VERSION ""

BS_:

BU_:

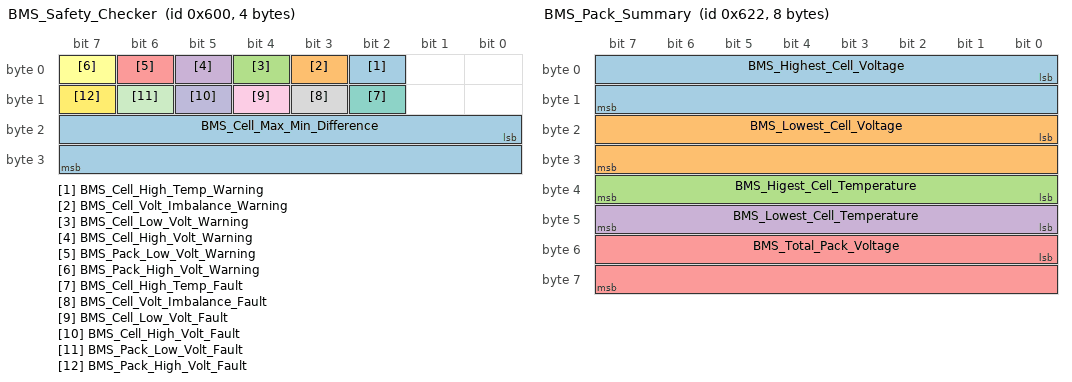
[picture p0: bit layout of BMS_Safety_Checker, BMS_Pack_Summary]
BO_ 1536 BMS_Safety_Checker: 4 Custom_BMS
SG_ BMS_Cell_High_Temp_Warning : 2|1@1- (1,0) [0|1] " " Custom_BMS
SG_ BMS_Cell_Volt_Imbalance_Warning : 3|1@1- (1,0) [0|1] " " Custom_BMS
SG_ BMS_Cell_Low_Volt_Warning : 4|1@1- (1,0) [0|1] " " Custom_BMS
SG_ BMS_Cell_High_Volt_Warning : 5|1@1- (1,0) [0|1] " " Custom_BMS
SG_ BMS_Pack_Low_Volt_Warning : 6|1@1- (1,0) [0|1] " " Custom_BMS
SG_ BMS_Pack_High_Volt_Warning : 7|1@1- (1,0) [0|1] " " Custom_BMS
SG_ BMS_Cell_High_Temp_Fault : 10|1@1- (1,0) [0|1] " " Custom_BMS
SG_ BMS_Cell_Volt_Imbalance_Fault : 11|1@1- (1,0) [0|1] " " Custom_BMS
SG_ BMS_Cell_Low_Volt_Fault : 12|1@1- (1,0) [0|1] " " Custom_BMS
SG_ BMS_Cell_High_Volt_Fault : 13|1@1- (1,0) [0|1] " " Custom_BMS
SG_ BMS_Pack_Low_Volt_Fault : 14|1@1- (1,0) [0|1] " " Custom_BMS
SG_ BMS_Pack_High_Volt_Fault : 15|1@1- (1,0) [0|1] " " Custom_BMS
SG_ BMS_Cell_Max_Min_Difference : 16|16@1+ (0.0001,0) [0|6.5535] "V" Custom_BMS

BO_ 1540 BMS_Balance_Enable: 1 Custom_BMS
SG_ BMS_Balance_Enable : 0|1@1- (1,0) [0|1] " " Custom_BMS

BO_ 1569 BMS_State_of_Charge: 7 Custom_BMS
SG_ BMS_Capacity : 0|16@1+ (1,0) [0|65535] "mAh" Custom_BMS
SG_ BMS_HV_Sense_Pack_Voltage: 16|16@1+ (0.01,0) [0|65535] "V" Custom_BMS
SG_ BMS_Current : 32|32@1+ (1,0) [0|4.29497e+009] "mA" Custom_BMS

BO_ 1571 BMS_Balance_Status_M1_to_M4: 8 Custom_BMS
SG_ BMS_M1_Cell_1 : 0|1@1- (1,0) [0|1] " " Custom_BMS
SG_ BMS_M1_Cell_2 : 1|1@1- (1,0) [0|1] " " Custom_BMS
SG_ BMS_M1_Cell_3 : 2|1@1- (1,0) [0|1] " " Custom_BMS
SG_ BMS_M1_Cell_4 : 3|1@1- (1,0) [0|1] " " Custom_BMS
SG_ BMS_M1_Cell_5 : 4|1@1- (1,0) [0|1] " " Custom_BMS
SG_ BMS_M1_Cell_6 : 5|1@1- (1,0) [0|1] " " Custom_BMS
SG_ BMS_M1_Cell_7 : 6|1@1- (1,0) [0|1] " " Custom_BMS
SG_ BMS_M1_Cell_8 : 7|1@1- (1,0) [0|1] " " Custom_BMS
SG_ BMS_M1_Cell_9 : 8|1@1- (1,0) [0|1] " " Custom_BMS
SG_ BMS_M1_Cell_10 : 9|1@1- (1,0) [0|1] " " Custom_BMS
SG_ BMS_M1_Cell_11 : 10|1@1- (1,0) [0|1] " " Custom_BMS
SG_ BMS_M1_Cell_12 : 11|1@1- (1,0) [0|1] " " Custom_BMS
SG_ BMS_M1_Cell_13 : 12|1@1- (1,0) [0|1] " " Custom_BMS
SG_ BMS_M1_Cell_14 : 13|1@1- (1,0) [0|1] " " Custom_BMS
SG_ BMS_M2_Cell_1 : 16|1@1- (1,0) [0|1] " " Custom_BMS
SG_ BMS_M2_Cell_2 : 17|1@1- (1,0) [0|1] " " Custom_BMS
SG_ BMS_M2_Cell_3 : 18|1@1- (1,0) [0|1] " " Custom_BMS
SG_ BMS_M2_Cell_4 : 19|1@1- (1,0) [0|1] " " Custom_BMS
SG_ BMS_M2_Cell_5 : 20|1@1- (1,0) [0|1] " " Custom_BMS
SG_ BMS_M2_Cell_6 : 21|1@1- (1,0) [0|1] " " Custom_BMS
SG_ BMS_M2_Cell_7 : 22|1@1- (1,0) [0|1] " " Custom_BMS
SG_ BMS_M2_Cell_8 : 23|1@1- (1,0) [0|1] " " Custom_BMS
SG_ BMS_M2_Cell_9 : 24|1@1- (1,0) [0|1] " " Custom_BMS
SG_ BMS_M2_Cell_10 : 25|1@1- (1,0) [0|1] " " Custom_BMS
SG_ BMS_M2_Cell_11 : 26|1@1- (1,0) [0|1] " " Custom_BMS
SG_ BMS_M2_Cell_12 : 27|1@1- (1,0) [0|1] " " Custom_BMS
SG_ BMS_M2_Cell_13 : 28|1@1- (1,0) [0|1] " " Custom_BMS
SG_ BMS_M2_Cell_14 : 29|1@1- (1,0) [0|1] " " Custom_BMS
SG_ BMS_M3_Cell_1 : 32|1@1- (1,0) [0|1] " " Custom_BMS
SG_ BMS_M3_Cell_2 : 33|1@1- (1,0) [0|1] " " Custom_BMS
SG_ BMS_M3_Cell_3 : 34|1@1- (1,0) [0|1] " " Custom_BMS
SG_ BMS_M3_Cell_4 : 35|1@1- (1,0) [0|1] " " Custom_BMS
SG_ BMS_M3_Cell_5 : 36|1@1- (1,0) [0|1] " " Custom_BMS
SG_ BMS_M3_Cell_6 : 37|1@1- (1,0) [0|1] " " Custom_BMS
SG_ BMS_M3_Cell_7 : 38|1@1- (1,0) [0|1] " " Custom_BMS
SG_ BMS_M3_Cell_8 : 39|1@1- (1,0) [0|1] " " Custom_BMS
SG_ BMS_M3_Cell_9 : 40|1@1- (1,0) [0|1] " " Custom_BMS
SG_ BMS_M3_Cell_10 : 41|1@1- (1,0) [0|1] " " Custom_BMS
SG_ BMS_M3_Cell_11 : 42|1@1- (1,0) [0|1] " " Custom_BMS
SG_ BMS_M3_Cell_12 : 43|1@1- (1,0) [0|1] " " Custom_BMS
SG_ BMS_M3_Cell_13 : 44|1@1- (1,0) [0|1] " " Custom_BMS
SG_ BMS_M3_Cell_14 : 45|1@1- (1,0) [0|1] " " Custom_BMS
SG_ BMS_M4_Cell_1 : 48|1@1- (1,0) [0|1] " " Custom_BMS
SG_ BMS_M4_Cell_2 : 49|1@1- (1,0) [0|1] " " Custom_BMS
SG_ BMS_M4_Cell_3 : 50|1@1- (1,0) [0|1] " " Custom_BMS
SG_ BMS_M4_Cell_4 : 51|1@1- (1,0) [0|1] " " Custom_BMS
SG_ BMS_M4_Cell_5 : 52|1@1- (1,0) [0|1] " " Custom_BMS
SG_ BMS_M4_Cell_6 : 53|1@1- (1,0) [0|1] " " Custom_BMS
SG_ BMS_M4_Cell_7 : 54|1@1- (1,0) [0|1] " " Custom_BMS
SG_ BMS_M4_Cell_8 : 55|1@1- (1,0) [0|1] " " Custom_BMS
SG_ BMS_M4_Cell_9 : 56|1@1- (1,0) [0|1] " " Custom_BMS
SG_ BMS_M4_Cell_10 : 57|1@1- (1,0) [0|1] " " Custom_BMS
SG_ BMS_M4_Cell_11 : 58|1@1- (1,0) [0|1] " " Custom_BMS
SG_ BMS_M4_Cell_12 : 59|1@1- (1,0) [0|1] " " Custom_BMS
SG_ BMS_M4_Cell_13 : 60|1@1- (1,0) [0|1] " " Custom_BMS
SG_ BMS_M4_Cell_14 : 61|1@1- (1,0) [0|1] " " Custom_BMS

BO_ 1572 BMS_Balance_Status_M5_to_M8: 8 Custom_BMS
SG_ BMS_M5_Cell_1 : 0|1@1- (1,0) [0|1] " " Custom_BMS
SG_ BMS_M5_Cell_2 : 1|1@1- (1,0) [0|1] " " Custom_BMS
SG_ BMS_M5_Cell_3 : 2|1@1- (1,0) [0|1] " " Custom_BMS
SG_ BMS_M5_Cell_4 : 3|1@1- (1,0) [0|1] " " Custom_BMS
SG_ BMS_M5_Cell_5 : 4|1@1- (1,0) [0|1] " " Custom_BMS
SG_ BMS_M5_Cell_6 : 5|1@1- (1,0) [0|1] " " Custom_BMS
SG_ BMS_M5_Cell_7 : 6|1@1- (1,0) [0|1] " " Custom_BMS
SG_ BMS_M5_Cell_8 : 7|1@1- (1,0) [0|1] " " Custom_BMS
SG_ BMS_M5_Cell_9 : 8|1@1- (1,0) [0|1] " " Custom_BMS
SG_ BMS_M5_Cell_10 : 9|1@1- (1,0) [0|1] " " Custom_BMS
SG_ BMS_M5_Cell_11 : 10|1@1- (1,0) [0|1] " " Custom_BMS
SG_ BMS_M5_Cell_12 : 11|1@1- (1,0) [0|1] " " Custom_BMS
SG_ BMS_M5_Cell_13 : 12|1@1- (1,0) [0|1] " " Custom_BMS
SG_ BMS_M5_Cell_14 : 13|1@1- (1,0) [0|1] " " Custom_BMS
SG_ BMS_M6_Cell_1 : 16|1@1- (1,0) [0|1] " " Custom_BMS
SG_ BMS_M6_Cell_2 : 17|1@1- (1,0) [0|1] " " Custom_BMS
SG_ BMS_M6_Cell_3 : 18|1@1- (1,0) [0|1] " " Custom_BMS
SG_ BMS_M6_Cell_4 : 19|1@1- (1,0) [0|1] " " Custom_BMS
SG_ BMS_M6_Cell_5 : 20|1@1- (1,0) [0|1] " " Custom_BMS
SG_ BMS_M6_Cell_6 : 21|1@1- (1,0) [0|1] " " Custom_BMS
SG_ BMS_M6_Cell_7 : 22|1@1- (1,0) [0|1] " " Custom_BMS
SG_ BMS_M6_Cell_8 : 23|1@1- (1,0) [0|1] " " Custom_BMS
SG_ BMS_M6_Cell_9 : 24|1@1- (1,0) [0|1] " " Custom_BMS
SG_ BMS_M6_Cell_10 : 25|1@1- (1,0) [0|1] " " Custom_BMS
SG_ BMS_M6_Cell_11 : 26|1@1- (1,0) [0|1] " " Custom_BMS
SG_ BMS_M6_Cell_12 : 27|1@1- (1,0) [0|1] " " Custom_BMS
SG_ BMS_M6_Cell_13 : 28|1@1- (1,0) [0|1] " " Custom_BMS
SG_ BMS_M6_Cell_14 : 29|1@1- (1,0) [0|1] " " Custom_BMS
SG_ BMS_M7_Cell_1 : 32|1@1- (1,0) [0|1] " " Custom_BMS
SG_ BMS_M7_Cell_2 : 33|1@1- (1,0) [0|1] " " Custom_BMS
SG_ BMS_M7_Cell_3 : 34|1@1- (1,0) [0|1] " " Custom_BMS
SG_ BMS_M7_Cell_4 : 35|1@1- (1,0) [0|1] " " Custom_BMS
SG_ BMS_M7_Cell_5 : 36|1@1- (1,0) [0|1] " " Custom_BMS
SG_ BMS_M7_Cell_6 : 37|1@1- (1,0) [0|1] " " Custom_BMS
SG_ BMS_M7_Cell_7 : 38|1@1- (1,0) [0|1] " " Custom_BMS
SG_ BMS_M7_Cell_8 : 39|1@1- (1,0) [0|1] " " Custom_BMS
SG_ BMS_M7_Cell_9 : 40|1@1- (1,0) [0|1] " " Custom_BMS
SG_ BMS_M7_Cell_10 : 41|1@1- (1,0) [0|1] " " Custom_BMS
SG_ BMS_M7_Cell_11 : 42|1@1- (1,0) [0|1] " " Custom_BMS
SG_ BMS_M7_Cell_12 : 43|1@1- (1,0) [0|1] " " Custom_BMS
SG_ BMS_M7_Cell_13 : 44|1@1- (1,0) [0|1] " " Custom_BMS
SG_ BMS_M7_Cell_14 : 45|1@1- (1,0) [0|1] " " Custom_BMS
SG_ BMS_M8_Cell_1 : 48|1@1- (1,0) [0|1] " " Custom_BMS
SG_ BMS_M8_Cell_2 : 49|1@1- (1,0) [0|1] " " Custom_BMS
SG_ BMS_M8_Cell_3 : 50|1@1- (1,0) [0|1] " " Custom_BMS
SG_ BMS_M8_Cell_4 : 51|1@1- (1,0) [0|1] " " Custom_BMS
SG_ BMS_M8_Cell_5 : 52|1@1- (1,0) [0|1] " " Custom_BMS
SG_ BMS_M8_Cell_6 : 53|1@1- (1,0) [0|1] " " Custom_BMS
SG_ BMS_M8_Cell_7 : 54|1@1- (1,0) [0|1] " " Custom_BMS
SG_ BMS_M8_Cell_8 : 55|1@1- (1,0) [0|1] " " Custom_BMS
SG_ BMS_M8_Cell_9 : 56|1@1- (1,0) [0|1] " " Custom_BMS
SG_ BMS_M8_Cell_10 : 57|1@1- (1,0) [0|1] " " Custom_BMS
SG_ BMS_M8_Cell_11 : 58|1@1- (1,0) [0|1] " " Custom_BMS
SG_ BMS_M8_Cell_12 : 59|1@1- (1,0) [0|1] " " Custom_BMS
SG_ BMS_M8_Cell_13 : 60|1@1- (1,0) [0|1] " " Custom_BMS
SG_ BMS_M8_Cell_14 : 61|1@1- (1,0) [0|1] " " Custom_BMS

BO_ 1573 BMS_Balance_Status_M9_to_M10: 8 Custom_BMS
SG_ BMS_M9_Cell_1 : 0|1@1- (1,0) [0|1] " " Custom_BMS
SG_ BMS_M9_Cell_2 : 1|1@1- (1,0) [0|1] " " Custom_BMS
SG_ BMS_M9_Cell_3 : 2|1@1- (1,0) [0|1] " " Custom_BMS
SG_ BMS_M9_Cell_4 : 3|1@1- (1,0) [0|1] " " Custom_BMS
SG_ BMS_M9_Cell_5 : 4|1@1- (1,0) [0|1] " " Custom_BMS
SG_ BMS_M9_Cell_6 : 5|1@1- (1,0) [0|1] " " Custom_BMS
SG_ BMS_M9_Cell_7 : 6|1@1- (1,0) [0|1] " " Custom_BMS
SG_ BMS_M9_Cell_8 : 7|1@1- (1,0) [0|1] " " Custom_BMS
SG_ BMS_M9_Cell_9 : 8|1@1- (1,0) [0|1] " " Custom_BMS
SG_ BMS_M9_Cell_10 : 9|1@1- (1,0) [0|1] " " Custom_BMS
SG_ BMS_M9_Cell_11 : 10|1@1- (1,0) [0|1] " " Custom_BMS
SG_ BMS_M9_Cell_12 : 11|1@1- (1,0) [0|1] " " Custom_BMS
SG_ BMS_M9_Cell_13 : 12|1@1- (1,0) [0|1] " " Custom_BMS
SG_ BMS_M9_Cell_14 : 13|1@1- (1,0) [0|1] " " Custom_BMS
SG_ BMS_M10_Cell_1 : 16|1@1- (1,0) [0|1] " " Custom_BMS
SG_ BMS_M10_Cell_2 : 17|1@1- (1,0) [0|1] " " Custom_BMS
SG_ BMS_M10_Cell_3 : 18|1@1- (1,0) [0|1] " " Custom_BMS
SG_ BMS_M10_Cell_4 : 19|1@1- (1,0) [0|1] " " Custom_BMS
SG_ BMS_M10_Cell_5 : 20|1@1- (1,0) [0|1] " " Custom_BMS
SG_ BMS_M10_Cell_6 : 21|1@1- (1,0) [0|1] " " Custom_BMS
SG_ BMS_M10_Cell_7 : 22|1@1- (1,0) [0|1] " " Custom_BMS
SG_ BMS_M10_Cell_8 : 23|1@1- (1,0) [0|1] " " Custom_BMS
SG_ BMS_M10_Cell_9 : 24|1@1- (1,0) [0|1] " " Custom_BMS
SG_ BMS_M10_Cell_10 : 25|1@1- (1,0) [0|1] " " Custom_BMS
SG_ BMS_M10_Cell_11 : 26|1@1- (1,0) [0|1] " " Custom_BMS
SG_ BMS_M10_Cell_12 : 27|1@1- (1,0) [0|1] " " Custom_BMS
SG_ BMS_M10_Cell_13 : 28|1@1- (1,0) [0|1] " " Custom_BMS
SG_ BMS_M10_Cell_14 : 29|1@1- (1,0) [0|1] " " Custom_BMS

BO_ 1570 BMS_Pack_Summary: 8 Custom_BMS
SG_ BMS_Highest_Cell_Voltage : 0|16@1- (0.001,0) [-32.768|32.767] "V" Custom_BMS
SG_ BMS_Lowest_Cell_Voltage : 16|16@1- (0.001,0) [-32.768|32.767] "V" Custom_BMS
SG_ BMS_Higest_Cell_Temperature : 32|8@1+ (1,0) [0|255] "C" Custom_BMS
SG_ BMS_Lowest_Cell_Temperature : 40|8@1+ (1,0) [0|255] "C" Custom_BMS
SG_ BMS_Total_Pack_Voltage   : 48|16@1- (0.001,0) [-32.768|32.767] "V" Custom_BMS

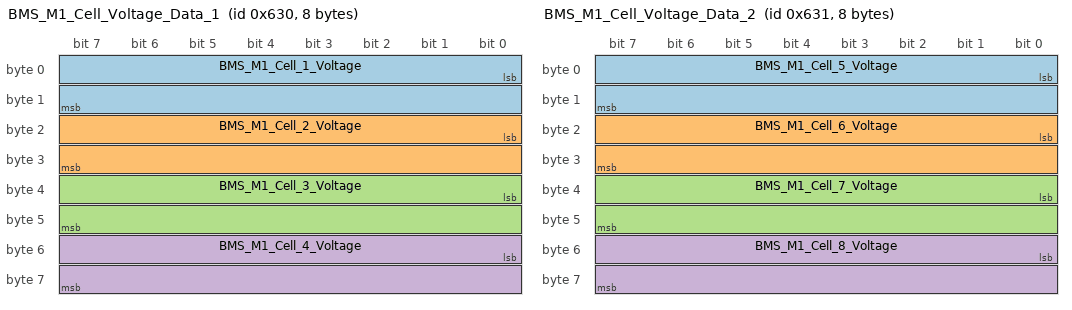
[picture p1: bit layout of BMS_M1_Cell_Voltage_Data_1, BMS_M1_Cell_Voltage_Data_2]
BO_ 1584 BMS_M1_Cell_Voltage_Data_1: 8 Custom_BMS
SG_ BMS_M1_Cell_1_Voltage : 0|16@1- (0.001,0) [-32.768|32.767] "V" Custom_BMS
SG_ BMS_M1_Cell_2_Voltage : 16|16@1- (0.001,0) [-32.768|32.767] "V" Custom_BMS
SG_ BMS_M1_Cell_3_Voltage : 32|16@1- (0.001,0) [-32.768|32.767] "V" Custom_BMS
SG_ BMS_M1_Cell_4_Voltage : 48|16@1- (0.001,0) [-32.768|32.767] "V" Custom_BMS

BO_ 1585 BMS_M1_Cell_Voltage_Data_2: 8 Custom_BMS
SG_ BMS_M1_Cell_5_Voltage : 0|16@1- (0.001,0) [-32.768|32.767] "V" Custom_BMS
SG_ BMS_M1_Cell_6_Voltage : 16|16@1- (0.001,0) [-32.768|32.767] "V" Custom_BMS
SG_ BMS_M1_Cell_7_Voltage : 32|16@1- (0.001,0) [-32.768|32.767] "V" Custom_BMS
SG_ BMS_M1_Cell_8_Voltage : 48|16@1- (0.001,0) [-32.768|32.767] "V" Custom_BMS

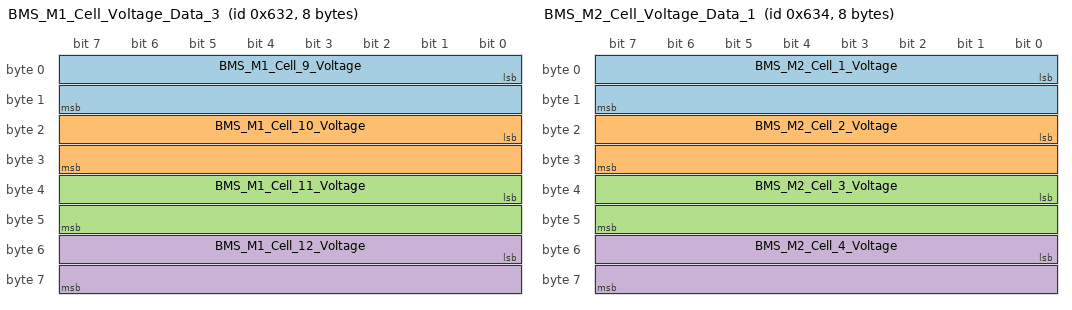
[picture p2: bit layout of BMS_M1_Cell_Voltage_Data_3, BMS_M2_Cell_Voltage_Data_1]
BO_ 1586 BMS_M1_Cell_Voltage_Data_3: 8 Custom_BMS
SG_ BMS_M1_Cell_9_Voltage  : 0|16@1- (0.001,0) [-32.768|32.767] "V" Custom_BMS
SG_ BMS_M1_Cell_10_Voltage : 16|16@1- (0.001,0) [-32.768|32.767] "V" Custom_BMS
SG_ BMS_M1_Cell_11_Voltage : 32|16@1- (0.001,0) [-32.768|32.767] "V" Custom_BMS
SG_ BMS_M1_Cell_12_Voltage : 48|16@1- (0.001,0) [-32.768|32.767] "V" Custom_BMS

BO_ 1587 BMS_M1_Cell_Voltage_Data_4: 4 Custom_BMS
SG_ BMS_M1_Cell_13_Voltage : 0|16@1- (0.001,0) [-32.768|32.767] "V" Custom_BMS
SG_ BMS_M1_Cell_14_Voltage : 16|16@1- (0.001,0) [-32.768|32.767] "V" Custom_BMS	CM_ check

BO_ 1588 BMS_M2_Cell_Voltage_Data_1: 8 Custom_BMS
SG_ BMS_M2_Cell_1_Voltage : 0|16@1- (0.001,0) [-32.768|32.767] "V" Custom_BMS
SG_ BMS_M2_Cell_2_Voltage : 16|16@1- (0.001,0) [-32.768|32.767] "V" Custom_BMS
SG_ BMS_M2_Cell_3_Voltage : 32|16@1- (0.001,0) [-32.768|32.767] "V" Custom_BMS
SG_ BMS_M2_Cell_4_Voltage : 48|16@1- (0.001,0) [-32.768|32.767] "V" Custom_BMS

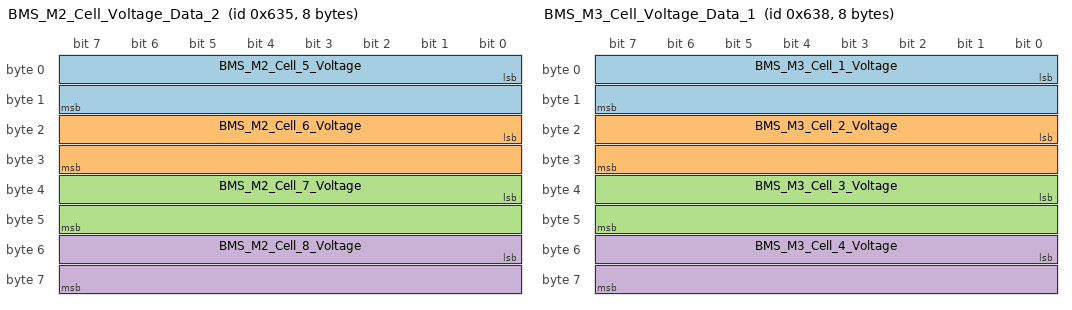
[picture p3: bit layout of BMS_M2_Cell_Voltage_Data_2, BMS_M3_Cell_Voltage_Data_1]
BO_ 1589 BMS_M2_Cell_Voltage_Data_2: 8 Custom_BMS
SG_ BMS_M2_Cell_5_Voltage : 0|16@1- (0.001,0) [-32.768|32.767] "V" Custom_BMS
SG_ BMS_M2_Cell_6_Voltage : 16|16@1- (0.001,0) [-32.768|32.767] "V" Custom_BMS
SG_ BMS_M2_Cell_7_Voltage : 32|16@1- (0.001,0) [-32.768|32.767] "V" Custom_BMS
SG_ BMS_M2_Cell_8_Voltage : 48|16@1- (0.001,0) [-32.768|32.767] "V" Custom_BMS

BO_ 1590 BMS_M2_Cell_Voltage_Data_3: 8 Custom_BMS
SG_ BMS_M2_Cell_9_Voltage  : 0|16@1- (0.001,0) [-32.768|32.767] "V" Custom_BMS
SG_ BMS_M2_Cell_10_Voltage : 16|16@1- (0.001,0) [-32.768|32.767] "V" Custom_BMS
SG_ BMS_M2_Cell_11_Voltage : 32|16@1- (0.001,0) [-32.768|32.767] "V" Custom_BMS
SG_ BMS_M2_Cell_12_Voltage : 48|16@1- (0.001,0) [-32.768|32.767] "V" Custom_BMS

B0_ 1591 BMS_M2_Cell_Voltage_data_4: 4 Custom_BMS
SG_ BMS_M2_Cell_13_Voltage : 0|16@1- (0.001,0) [-32.768|32.767] "V" Custom_BMS
SG_ BMS_M2_Cell_14_voltage : 16|16@1- (0.001,0) [-32.768|32.767] "V" Custom_BMS	CM_check

BO_ 1592 BMS_M3_Cell_Voltage_Data_1: 8 Custom_BMS
SG_ BMS_M3_Cell_1_Voltage : 0|16@1- (0.001,0) [-32.768|32.767] "V" Custom_BMS
SG_ BMS_M3_Cell_2_Voltage : 16|16@1- (0.001,0) [-32.768|32.767] "V" Custom_BMS
SG_ BMS_M3_Cell_3_Voltage : 32|16@1- (0.001,0) [-32.768|32.767] "V" Custom_BMS
SG_ BMS_M3_Cell_4_Voltage : 48|16@1- (0.001,0) [-32.768|32.767] "V" Custom_BMS

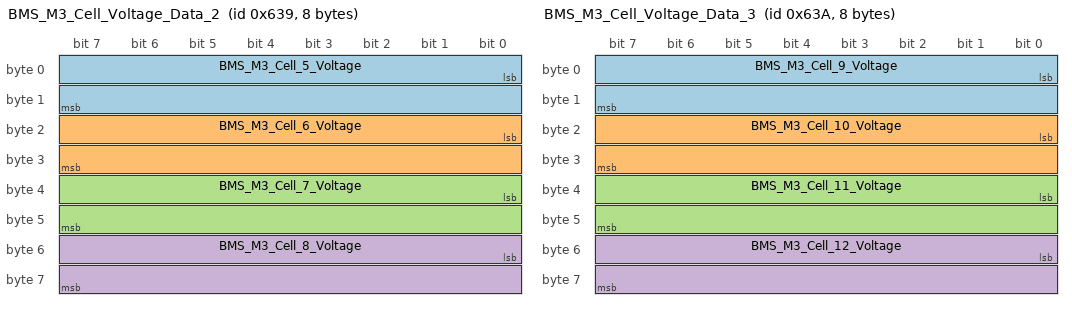
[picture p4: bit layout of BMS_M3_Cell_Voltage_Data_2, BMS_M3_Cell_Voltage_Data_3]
BO_ 1593 BMS_M3_Cell_Voltage_Data_2: 8 Custom_BMS
SG_ BMS_M3_Cell_5_Voltage : 0|16@1- (0.001,0) [-32.768|32.767] "V" Custom_BMS
SG_ BMS_M3_Cell_6_Voltage : 16|16@1- (0.001,0) [-32.768|32.767] "V" Custom_BMS
SG_ BMS_M3_Cell_7_Voltage : 32|16@1- (0.001,0) [-32.768|32.767] "V" Custom_BMS
SG_ BMS_M3_Cell_8_Voltage : 48|16@1- (0.001,0) [-32.768|32.767] "V" Custom_BMS

BO_ 1594 BMS_M3_Cell_Voltage_Data_3: 8 Custom_BMS
SG_ BMS_M3_Cell_9_Voltage  : 0|16@1- (0.001,0) [-32.768|32.767] "V" Custom_BMS
SG_ BMS_M3_Cell_10_Voltage : 16|16@1- (0.001,0) [-32.768|32.767] "V" Custom_BMS
SG_ BMS_M3_Cell_11_Voltage : 32|16@1- (0.001,0) [-32.768|32.767] "V" Custom_BMS
SG_ BMS_M3_Cell_12_Voltage : 48|16@1- (0.001,0) [-32.768|32.767] "V" Custom_BMS

BO_ 1595 BMS_M3_Cell_Voltage_Data_4: 4 Custom_BMS
SG_ BMS_M3_Cell_13_Voltage : 0|16@1- (0.001,0) [-32.768|32.767] "V" Custom_BMS
SG_ BMS_M3_Cell_14_Voltage : 16|16@1- (0.001,0) [-32.768|32.767] "V" Custom_BMS	CM_ check

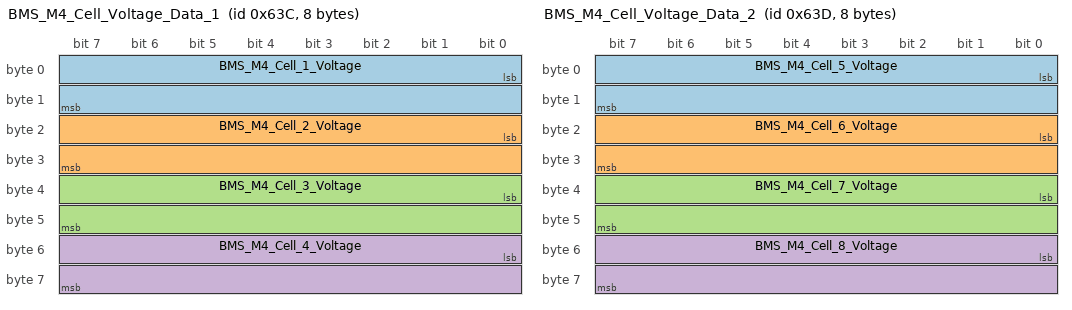
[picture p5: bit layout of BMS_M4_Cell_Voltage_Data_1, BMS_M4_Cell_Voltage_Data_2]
BO_ 1596 BMS_M4_Cell_Voltage_Data_1: 8 Custom_BMS
SG_ BMS_M4_Cell_1_Voltage : 0|16@1- (0.001,0) [-32.768|32.767] "V" Custom_BMS
SG_ BMS_M4_Cell_2_Voltage : 16|16@1- (0.001,0) [-32.768|32.767] "V" Custom_BMS
SG_ BMS_M4_Cell_3_Voltage : 32|16@1- (0.001,0) [-32.768|32.767] "V" Custom_BMS
SG_ BMS_M4_Cell_4_Voltage : 48|16@1- (0.001,0) [-32.768|32.767] "V" Custom_BMS

BO_ 1597 BMS_M4_Cell_Voltage_Data_2: 8 Custom_BMS
SG_ BMS_M4_Cell_5_Voltage : 0|16@1- (0.001,0) [-32.768|32.767] "V" Custom_BMS
SG_ BMS_M4_Cell_6_Voltage : 16|16@1- (0.001,0) [-32.768|32.767] "V" Custom_BMS
SG_ BMS_M4_Cell_7_Voltage : 32|16@1- (0.001,0) [-32.768|32.767] "V" Custom_BMS
SG_ BMS_M4_Cell_8_Voltage : 48|16@1- (0.001,0) [-32.768|32.767] "V" Custom_BMS

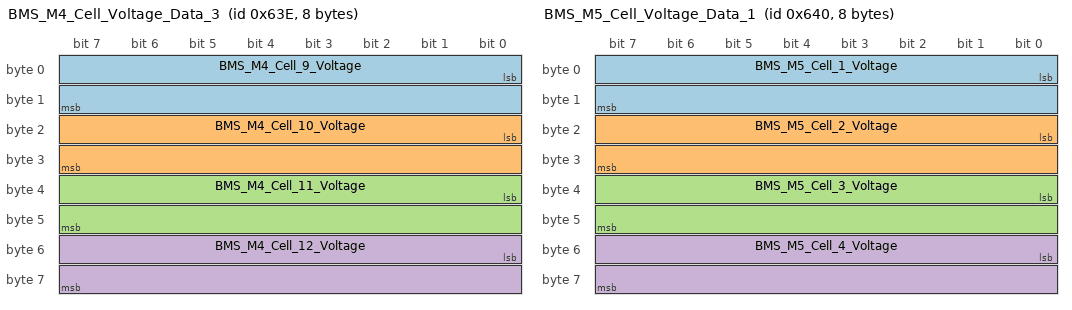
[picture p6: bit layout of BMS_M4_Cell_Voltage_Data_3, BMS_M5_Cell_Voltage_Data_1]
BO_ 1598 BMS_M4_Cell_Voltage_Data_3: 8 Custom_BMS
SG_ BMS_M4_Cell_9_Voltage  : 0|16@1- (0.001,0) [-32.768|32.767] "V" Custom_BMS
SG_ BMS_M4_Cell_10_Voltage : 16|16@1- (0.001,0) [-32.768|32.767] "V" Custom_BMS
SG_ BMS_M4_Cell_11_Voltage : 32|16@1- (0.001,0) [-32.768|32.767] "V" Custom_BMS
SG_ BMS_M4_Cell_12_Voltage : 48|16@1- (0.001,0) [-32.768|32.767] "V" Custom_BMS

BO_ 1599 BMS_M4_Cell_Voltage_Data_4: 4 Custom_BMS
SG_ BMS_M4_Cell_13_Voltage : 0|16@1- (0.001,0) [-32.768|32.767] "V" Custom_BMS
SG_ BMS_M4_Cell_14_Voltage : 16|16@1- (0.001,0) [-32.768|32.767] "V" Custom_BMS	CM_ check 32 bits

BO_ 1600 BMS_M5_Cell_Voltage_Data_1: 8 Custom_BMS
SG_ BMS_M5_Cell_1_Voltage : 0|16@1- (0.001,0) [-32.768|32.767] "V" Custom_BMS
SG_ BMS_M5_Cell_2_Voltage : 16|16@1- (0.001,0) [-32.768|32.767] "V" Custom_BMS
SG_ BMS_M5_Cell_3_Voltage : 32|16@1- (0.001,0) [-32.768|32.767] "V" Custom_BMS
SG_ BMS_M5_Cell_4_Voltage : 48|16@1- (0.001,0) [-32.768|32.767] "V" Custom_BMS

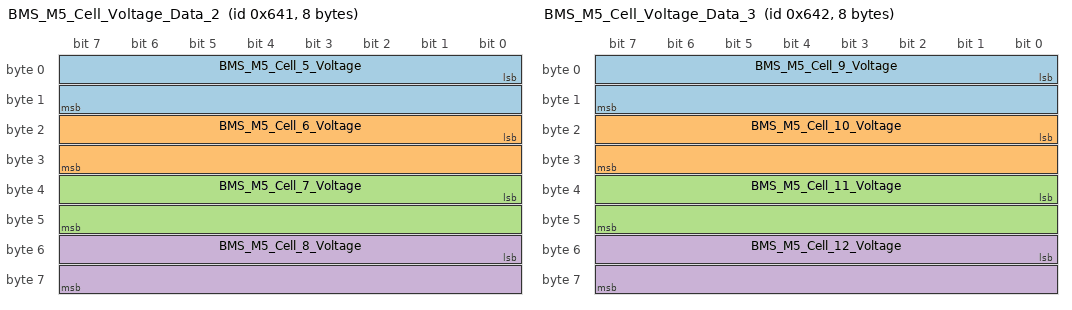
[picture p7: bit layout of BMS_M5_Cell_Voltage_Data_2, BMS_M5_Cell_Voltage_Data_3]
BO_ 1601 BMS_M5_Cell_Voltage_Data_2: 8 Custom_BMS
SG_ BMS_M5_Cell_5_Voltage : 0|16@1- (0.001,0) [-32.768|32.767] "V" Custom_BMS
SG_ BMS_M5_Cell_6_Voltage : 16|16@1- (0.001,0) [-32.768|32.767] "V" Custom_BMS
SG_ BMS_M5_Cell_7_Voltage : 32|16@1- (0.001,0) [-32.768|32.767] "V" Custom_BMS
SG_ BMS_M5_Cell_8_Voltage : 48|16@1- (0.001,0) [-32.768|32.767] "V" Custom_BMS

BO_ 1602 BMS_M5_Cell_Voltage_Data_3: 8 Custom_BMS
SG_ BMS_M5_Cell_9_Voltage  : 0|16@1- (0.001,0) [-32.768|32.767] "V" Custom_BMS
SG_ BMS_M5_Cell_10_Voltage : 16|16@1- (0.001,0) [-32.768|32.767] "V" Custom_BMS
SG_ BMS_M5_Cell_11_Voltage : 32|16@1- (0.001,0) [-32.768|32.767] "V" Custom_BMS
SG_ BMS_M5_Cell_12_Voltage : 48|16@1- (0.001,0) [-32.768|32.767] "V" Custom_BMS

BO_ 1603 BMS_M5_Cell_Voltage_Data_4: 4 Custom_BMS
SG_ BMS_M5_Cell_13_Voltage : 0|16@1- (0.001,0) [-32.768|32.767] "V" Custom_BMS
SG_ BMS_M5_Cell_14_Voltage : 16|16@1- (0.001,0) [-32.768|32.767] "V" Custom_BMS CM_check

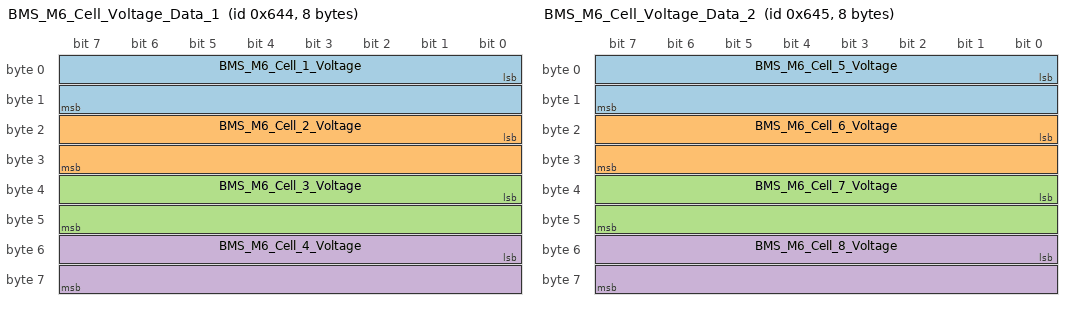
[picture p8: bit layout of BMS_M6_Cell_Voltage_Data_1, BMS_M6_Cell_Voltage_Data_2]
BO_ 1604 BMS_M6_Cell_Voltage_Data_1: 8 Custom_BMS
SG_ BMS_M6_Cell_1_Voltage : 0|16@1- (0.001,0) [-32.768|32.767] "V" Custom_BMS
SG_ BMS_M6_Cell_2_Voltage : 16|16@1- (0.001,0) [-32.768|32.767] "V" Custom_BMS
SG_ BMS_M6_Cell_3_Voltage : 32|16@1- (0.001,0) [-32.768|32.767] "V" Custom_BMS
SG_ BMS_M6_Cell_4_Voltage : 48|16@1- (0.001,0) [-32.768|32.767] "V" Custom_BMS

BO_ 1605 BMS_M6_Cell_Voltage_Data_2: 8 Custom_BMS
SG_ BMS_M6_Cell_5_Voltage : 0|16@1- (0.001,0) [-32.768|32.767] "V" Custom_BMS
SG_ BMS_M6_Cell_6_Voltage : 16|16@1- (0.001,0) [-32.768|32.767] "V" Custom_BMS
SG_ BMS_M6_Cell_7_Voltage : 32|16@1- (0.001,0) [-32.768|32.767] "V" Custom_BMS
SG_ BMS_M6_Cell_8_Voltage : 48|16@1- (0.001,0) [-32.768|32.767] "V" Custom_BMS

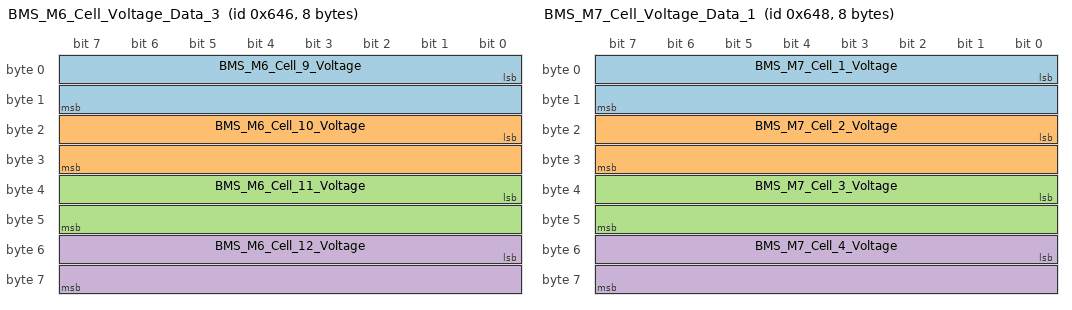
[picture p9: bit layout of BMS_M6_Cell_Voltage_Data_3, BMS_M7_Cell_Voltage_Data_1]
BO_ 1606 BMS_M6_Cell_Voltage_Data_3: 8 Custom_BMS
SG_ BMS_M6_Cell_9_Voltage  : 0|16@1- (0.001,0) [-32.768|32.767] "V" Custom_BMS
SG_ BMS_M6_Cell_10_Voltage : 16|16@1- (0.001,0) [-32.768|32.767] "V" Custom_BMS
SG_ BMS_M6_Cell_11_Voltage : 32|16@1- (0.001,0) [-32.768|32.767] "V" Custom_BMS
SG_ BMS_M6_Cell_12_Voltage : 48|16@1- (0.001,0) [-32.768|32.767] "V" Custom_BMS

BO_ 1607 BMS_M6_Cell_Voltage_Data_4: 4 Custom_BMS
SG_ BMS_M6_Cell_13_Voltage : 0|16@1- (0.001,0) [-32.768|32.767] "V" Custom_BMS
SG_ BMS_M6_Cell_14_Voltage : 16|16@1- (0.001,0) [-32.768|32.767] "V" Custom_BMS		CM_ check

BO_ 1608 BMS_M7_Cell_Voltage_Data_1: 8 Custom_BMS
SG_ BMS_M7_Cell_1_Voltage : 0|16@1- (0.001,0) [-32.768|32.767] "V" Custom_BMS
SG_ BMS_M7_Cell_2_Voltage : 16|16@1- (0.001,0) [-32.768|32.767] "V" Custom_BMS
SG_ BMS_M7_Cell_3_Voltage : 32|16@1- (0.001,0) [-32.768|32.767] "V" Custom_BMS
SG_ BMS_M7_Cell_4_Voltage : 48|16@1- (0.001,0) [-32.768|32.767] "V" Custom_BMS

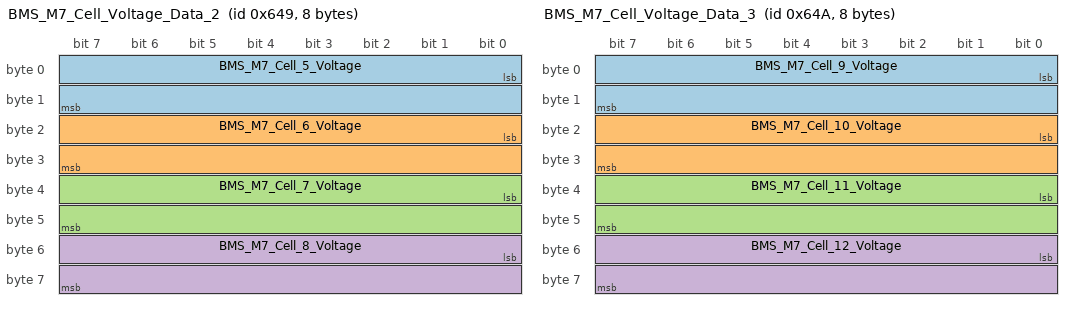
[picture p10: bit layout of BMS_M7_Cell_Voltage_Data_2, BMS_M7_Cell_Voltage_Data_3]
BO_ 1609 BMS_M7_Cell_Voltage_Data_2: 8 Custom_BMS
SG_ BMS_M7_Cell_5_Voltage : 0|16@1- (0.001,0) [-32.768|32.767] "V" Custom_BMS
SG_ BMS_M7_Cell_6_Voltage : 16|16@1- (0.001,0) [-32.768|32.767] "V" Custom_BMS
SG_ BMS_M7_Cell_7_Voltage : 32|16@1- (0.001,0) [-32.768|32.767] "V" Custom_BMS
SG_ BMS_M7_Cell_8_Voltage : 48|16@1- (0.001,0) [-32.768|32.767] "V" Custom_BMS

BO_ 1610 BMS_M7_Cell_Voltage_Data_3: 8 Custom_BMS
SG_ BMS_M7_Cell_9_Voltage  : 0|16@1- (0.001,0) [-32.768|32.767] "V" Custom_BMS
SG_ BMS_M7_Cell_10_Voltage : 16|16@1- (0.001,0) [-32.768|32.767] "V" Custom_BMS
SG_ BMS_M7_Cell_11_Voltage : 32|16@1- (0.001,0) [-32.768|32.767] "V" Custom_BMS
SG_ BMS_M7_Cell_12_Voltage : 48|16@1- (0.001,0) [-32.768|32.767] "V" Custom_BMS

BO_ 1611 BMS_M7_Cell_Voltage_Data_4: 4 Custom_BMS
SG_ BMS_M7_Cell_13_Voltage : 0|16@1- (0.001,0) [-32.768|32.767] "V" Custom_BMS
SG_ BMS_M7_Cell_14_Voltage : 16|16@1- (0.001,0) [-32.768|32.767] "V" Custom_BMS	CM_ check

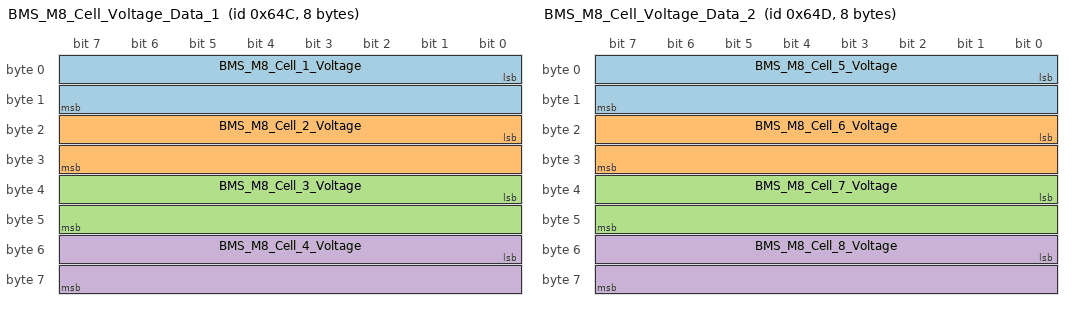
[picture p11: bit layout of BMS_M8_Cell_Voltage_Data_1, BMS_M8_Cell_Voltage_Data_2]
BO_ 1612 BMS_M8_Cell_Voltage_Data_1: 8 Custom_BMS
SG_ BMS_M8_Cell_1_Voltage : 0|16@1- (0.001,0) [-32.768|32.767] "V" Custom_BMS
SG_ BMS_M8_Cell_2_Voltage : 16|16@1- (0.001,0) [-32.768|32.767] "V" Custom_BMS
SG_ BMS_M8_Cell_3_Voltage : 32|16@1- (0.001,0) [-32.768|32.767] "V" Custom_BMS
SG_ BMS_M8_Cell_4_Voltage : 48|16@1- (0.001,0) [-32.768|32.767] "V" Custom_BMS

BO_ 1613 BMS_M8_Cell_Voltage_Data_2: 8 Custom_BMS
SG_ BMS_M8_Cell_5_Voltage : 0|16@1- (0.001,0) [-32.768|32.767] "V" Custom_BMS
SG_ BMS_M8_Cell_6_Voltage : 16|16@1- (0.001,0) [-32.768|32.767] "V" Custom_BMS
SG_ BMS_M8_Cell_7_Voltage : 32|16@1- (0.001,0) [-32.768|32.767] "V" Custom_BMS
SG_ BMS_M8_Cell_8_Voltage : 48|16@1- (0.001,0) [-32.768|32.767] "V" Custom_BMS

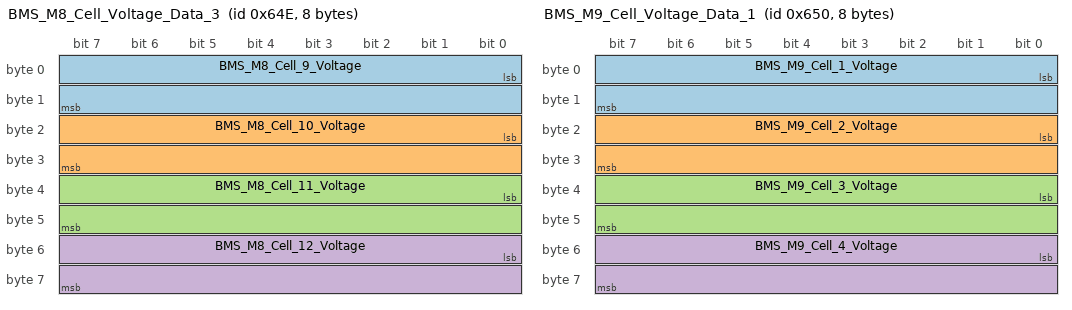
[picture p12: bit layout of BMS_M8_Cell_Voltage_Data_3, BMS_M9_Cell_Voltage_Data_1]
BO_ 1614 BMS_M8_Cell_Voltage_Data_3: 8 Custom_BMS
SG_ BMS_M8_Cell_9_Voltage  : 0|16@1- (0.001,0) [-32.768|32.767] "V" Custom_BMS
SG_ BMS_M8_Cell_10_Voltage : 16|16@1- (0.001,0) [-32.768|32.767] "V" Custom_BMS
SG_ BMS_M8_Cell_11_Voltage : 32|16@1- (0.001,0) [-32.768|32.767] "V" Custom_BMS
SG_ BMS_M8_Cell_12_Voltage : 48|16@1- (0.001,0) [-32.768|32.767] "V" Custom_BMS

BO_ 1615 BMS_M8_Cell_Voltage_Data_4: 4 Custom_BMS
SG_ BMS_M8_Cell_13_Voltage : 0|16@1- (0.001,0) [-32.768|32.767] "V" Custom_BMS
SG_ BMS_M8_Cell_14_Voltage : 16|16@1- (0.001,0) [-32.768|32.767] "V" Custom_BMS	CM_ check

BO_ 1616 BMS_M9_Cell_Voltage_Data_1: 8 Custom_BMS
SG_ BMS_M9_Cell_1_Voltage : 0|16@1- (0.001,0) [-32.768|32.767] "V" Custom_BMS
SG_ BMS_M9_Cell_2_Voltage : 16|16@1- (0.001,0) [-32.768|32.767] "V" Custom_BMS
SG_ BMS_M9_Cell_3_Voltage : 32|16@1- (0.001,0) [-32.768|32.767] "V" Custom_BMS
SG_ BMS_M9_Cell_4_Voltage : 48|16@1- (0.001,0) [-32.768|32.767] "V" Custom_BMS

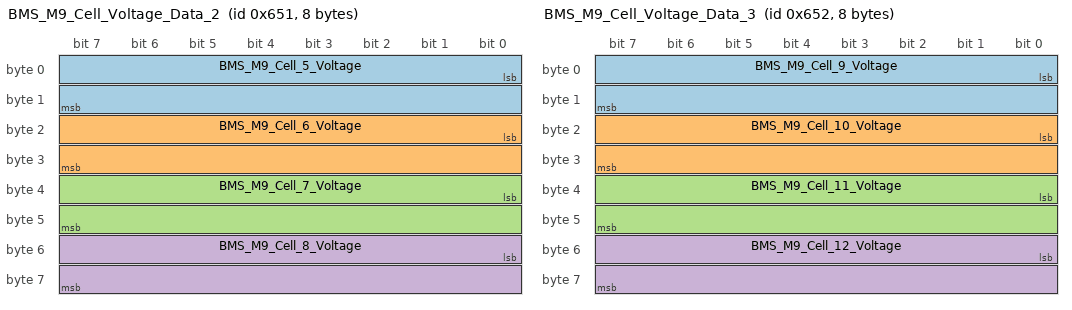
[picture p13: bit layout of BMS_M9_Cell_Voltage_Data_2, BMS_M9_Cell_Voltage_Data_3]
BO_ 1617 BMS_M9_Cell_Voltage_Data_2: 8 Custom_BMS
SG_ BMS_M9_Cell_5_Voltage : 0|16@1- (0.001,0) [-32.768|32.767] "V" Custom_BMS
SG_ BMS_M9_Cell_6_Voltage : 16|16@1- (0.001,0) [-32.768|32.767] "V" Custom_BMS
SG_ BMS_M9_Cell_7_Voltage : 32|16@1- (0.001,0) [-32.768|32.767] "V" Custom_BMS
SG_ BMS_M9_Cell_8_Voltage : 48|16@1- (0.001,0) [-32.768|32.767] "V" Custom_BMS

BO_ 1618 BMS_M9_Cell_Voltage_Data_3: 8 Custom_BMS
SG_ BMS_M9_Cell_9_Voltage  : 0|16@1- (0.001,0) [-32.768|32.767] "V" Custom_BMS
SG_ BMS_M9_Cell_10_Voltage : 16|16@1- (0.001,0) [-32.768|32.767] "V" Custom_BMS
SG_ BMS_M9_Cell_11_Voltage : 32|16@1- (0.001,0) [-32.768|32.767] "V" Custom_BMS
SG_ BMS_M9_Cell_12_Voltage : 48|16@1- (0.001,0) [-32.768|32.767] "V" Custom_BMS

BO_ 1619 BMS_M9_Cell_Voltage_Data_4: 4 Custom_BMS
SG_ BMS_M9_Cell_13_Voltage : 0|16@1- (0.001,0) [-32.768|32.767] "V" Custom_BMS
SG_ BMS_M9_Cell_14_Voltage : 16|16@1- (0.001,0) [-32.768|32.767] "V" Custom_BMS	CM_ check

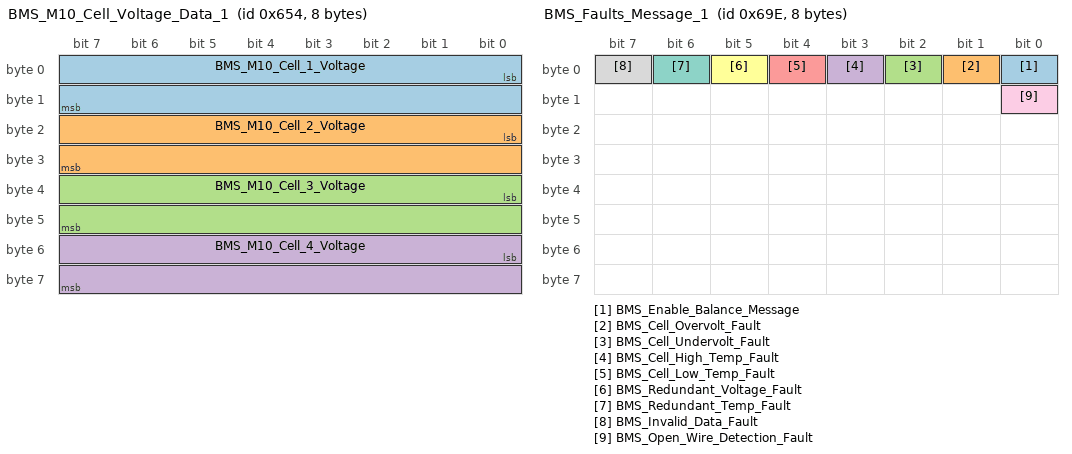
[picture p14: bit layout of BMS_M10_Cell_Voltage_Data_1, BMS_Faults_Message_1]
BO_ 1620 BMS_M10_Cell_Voltage_Data_1: 8 Custom_BMS
SG_ BMS_M10_Cell_1_Voltage : 0|16@1- (0.001,0) [-32.768|32.767] "V" Custom_BMS
SG_ BMS_M10_Cell_2_Voltage : 16|16@1- (0.001,0) [-32.768|32.767] "V" Custom_BMS
SG_ BMS_M10_Cell_3_Voltage : 32|16@1- (0.001,0) [-32.768|32.767] "V" Custom_BMS
SG_ BMS_M10_Cell_4_Voltage : 48|16@1- (0.001,0) [-32.768|32.767] "V" Custom_BMS

BO_ 1621 BMS_M10_Cell_Voltage_Data_2: 8 Custom_BMS
SG_ BMS_M10_Cell_5_Voltage : 0|16@1- (0.001,0) [-32.768|32.767] "V" Custom_BMS
SG_ BMS_M10_Cell_6_Voltage : 16|16@1- (0.001,0) [-32.768|32.767] "V" Custom_BMS
SG_ BMS_M10_Cell_7_Voltage : 32|16@1- (0.001,0) [-32.768|32.767] "V" Custom_BMS
SG_ BMS_M10_Cell_8_Voltage : 48|16@1- (0.001,0) [-32.768|32.767] "V" Custom_BMS

BO_ 1622 BMS_M10_Cell_Voltage_Data_3: 8 Custom_BMS
SG_ BMS_M10_Cell_9_Voltage  : 0|16@1- (0.001,0) [-32.768|32.767] "V" Custom_BMS
SG_ BMS_M10_Cell_10_Voltage : 16|16@1- (0.001,0) [-32.768|32.767] "V" Custom_BMS
SG_ BMS_M10_Cell_11_Voltage : 32|16@1- (0.001,0) [-32.768|32.767] "V" Custom_BMS
SG_ BMS_M10_Cell_12_Voltage : 48|16@1- (0.001,0) [-32.768|32.767] "V" Custom_BMS

BO_ 1623 BMS_M10_Cell_Voltage_Data_4: 4 Custom_BMS
SG_ BMS_M10_Cell_13_Voltage : 0|16@1- (0.001,0) [-32.768|32.767] "V" Custom_BMS
SG_ BMS_M10_Cell_14_Voltage : 16|16@1- (0.001,0) [-32.768|32.767] "V" Custom_BMS	CM_ check

BO_ 1664 BMS_M1_Cell_Thermistor_Data_1: 8 Custom_BMS
SG_ BMS_M1_Cell_position1_Thermistor : 0|16@1+ (1,0) [0|255] "C" Custom_BMS
SG_ BMS_M1_Cell_position2_Thermistor : 16|16@1+ (1,0) [0|255] "C" Custom_BMS CM_check changed to 16 bytes for each thermistor
SG_ BMS_M1_Cell_position3_Thermistor : 32|16@1+ (1,0) [0|255] "C" Custom_BMS
SG_ BMS_M1_Cell_position4_Thermistor : 48|16@1+ (1,0) [0|255] "C" Custom_BMS

BO_ 1665 BMS_M1_Cell_Thermistor_Data_2: 8 Custom_BMS
SG_ BMS_M1_Cell_position5_Thermistor : 0|16@1+ (1,0) [0|255] "C" Custom_BMS
SG_ BMS_M1_Cell_position6_Thermistor : 16|16@1+ (1,0) [0|255] "C" Custom_BMS
SG_ BMS_M1_Cell_position7_Thermistor : 32|16@1+ (1,0) [0|255] "C" Custom_BMS
SG_ BMS_M1_Cell_position8_Thermistor : 48|16@1+ (1,0) [0|255] "C" Custom_BMS CM_check thermistor 10 temp read    deleted pressure,humidity, atmosphere, dewpoint

BO_ 1666 BMS_M1_Cell_Thermistor_Data_3: 4 Custom_BMS
SG_ BMS_M1_Cell_position9_Thermistor  : 0|16@1+ (1,0) [0|255] "C" Custom_BMS CM_check add more stuff into the messages
SG_ BMS_M1_Cell_position10_Thermistor : 16|16@1+ (1,0) [0|255] "C" Custom_BMS

BO_ 1667 BMS_M2_Cell_Thermistor_Data_1: 8 Custom_BMS
SG_ BMS_M2_Cell_position1_Thermistor : 0|16@1+ (1,0) [0|255] "C" Custom_BMS
SG_ BMS_M2_Cell_position2_Thermistor : 16|16@1+ (1,0) [0|255] "C" Custom_BMS
SG_ BMS_M2_Cell_position3_Thermistor : 32|16@1+ (1,0) [0|255] "C" Custom_BMS
SG_ BMS_M2_Cell_position4_Thermistor : 48|16@1+ (1,0) [0|255] "C" Custom_BMS

BO_ 1668 BMS_M2_Cell_Thermistor_Data_2: 8 Custom_BMS
SG_ BMS_M2_Cell_position5_Thermistor : 0|16@1+ (1,0) [0|255] "C" Custom_BMS
SG_ BMS_M2_Cell_position6_Thermistor : 16|16@1+ (1,0) [0|255] "C" Custom_BMS
SG_ BMS_M2_Cell_position7_Thermistor : 32|16@1+ (1,0) [0|255] "C" Custom_BMS
SG_ BMS_M2_Cell_position8_Thermistor : 48|16@1+ (1,0) [0|255] "C" Custom_BMS

BO_ 1669 BMS_M2_Cell_Thermistor_Data_3: 4 Custom_BMS
SG_ BMS_M2_Cell_position9_Thermistor  : 0|16@1+ (1,0) [0|255] "C" Custom_BMS
SG_ BMS_M2_Cell_position10_Thermistor : 16|16@1+ (1,0) [0|255] "C" Custom_BMS CM_check thermistor 10 readings delete dew point, atmosphere temp,pressure, humidity

BO_ 1670 BMS_M3_Cell_Thermistor_Data_1: 8 Custom_BMS
SG_ BMS_M3_Cell_position1_Thermistor : 0|16@1+ (1,0) [0|255] "C" Custom_BMS
SG_ BMS_M3_Cell_position2_Thermistor : 16|16@1+ (1,0) [0|255] "C" Custom_BMS
SG_ BMS_M3_Cell_position3_Thermistor : 32|16@1+ (1,0) [0|255] "C" Custom_BMS
SG_ BMS_M3_Cell_position4_Thermistor : 48|16@1+ (1,0) [0|255] "C" Custom_BMS

BO_ 1671 BMS_M3_Cell_Thermistor_Data_2: 8 Custom_BMS
SG_ BMS_M3_Cell_position5_Thermistor : 0|16@1+ (1,0) [0|255] "C" Custom_BMS
SG_ BMS_M3_Cell_position6_Thermistor : 16|16@1+ (1,0) [0|255] "C" Custom_BMS
SG_ BMS_M3_Cell_position7_Thermistor : 32|16@1+ (1,0) [0|255] "C" Custom_BMS
SG_ BMS_M3_Cell_position8_Thermistor : 48|16@1+ (1,0) [0|255] "C" Custom_BMS

BO_ 1672 BMS_M3_Cell_Thermistor_Data_3: 4 Custom_BMS
SG_ BMS_M3_Cell_position9_Thermistor  : 0|16@1+ (1,0) [0|255] "C" Custom_BMS
SG_ BMS_M3_Cell_position10_Thermistor : 16|16@1+ (1,0) [0|255] "C" Custom_BMS CM_check thermistor 10 readings

BO_ 1673 BMS_M4_Cell_Thermistor_Data_1: 8 Custom_BMS
SG_ BMS_M4_Cell_position1_Thermistor : 0|16@1+ (1,0) [0|255] "C" Custom_BMS
SG_ BMS_M4_Cell_position2_Thermistor : 16|16@1+ (1,0) [0|255] "C" Custom_BMS
SG_ BMS_M4_Cell_position3_Thermistor : 32|16@1+ (1,0) [0|255] "C" Custom_BMS
SG_ BMS_M4_Cell_position4_Thermistor : 48|16@1+ (1,0) [0|255] "C" Custom_BMS

BO_ 1674 BMS_M4_Cell_Thermistor_Data_2: 8 Custom_BMS
SG_ BMS_M4_Cell_position5_Thermistor : 0|16@1+ (1,0) [0|255] "C" Custom_BMS
SG_ BMS_M4_Cell_position6_Thermistor : 16|16@1+ (1,0) [0|255] "C" Custom_BMS
SG_ BMS_M4_Cell_position7_Thermistor : 32|16@1+ (1,0) [0|255] "C" Custom_BMS
SG_ BMS_M4_Cell_position8_Thermistor : 48|16@1+ (1,0) [0|255] "C" Custom_BMS

BO_ 1675 BMS_M4_Cell_Thermistor_Data_3: 4 Custom_BMS
SG_ BMS_M4_Cell_position9_Thermistor  : 0|16@1+ (1,0) [0|255] "C" Custom_BMS
SG_ BMS_M4_Cell_position10_Thermistor : 16|16@1+ (1,0) [0|255] "C" Custom_BMS CM_check thermister 10 readings

BO_ 1676 BMS_M5_Cell_Thermistor_Data_1: 8 Custom_BMS
SG_ BMS_M5_Cell_position1_Thermistor : 0|16@1+ (1,0) [0|255] "C" Custom_BMS
SG_ BMS_M5_Cell_position2_Thermistor : 16|16@1+ (1,0) [0|255] "C" Custom_BMS
SG_ BMS_M5_Cell_position3_Thermistor : 32|16@1+ (1,0) [0|255] "C" Custom_BMS
SG_ BMS_M5_Cell_position4_Thermistor : 48|16@1+ (1,0) [0|255] "C" Custom_BMS

BO_ 1677 BMS_M5_Cell_Thermistor_Data_2: 8 Custom_BMSBO_ 1666 BMS_M2_Cell_Thermistor_Data_1: 8 Custom_BMS
SG_ BMS_M5_Cell_position5_Thermistor : 0|16@1+ (1,0) [0|255] "C" Custom_BMS
SG_ BMS_M5_Cell_position6_Thermistor : 16|16@1+ (1,0) [0|255] "C" Custom_BMS
SG_ BMS_M5_Cell_position7_Thermistor : 32|16@1+ (1,0) [0|255] "C" Custom_BMS
SG_ BMS_M5_Cell_position8_Thermistor : 48|16@1+ (1,0) [0|255] "C" Custom_BMS

BO_ 1678 BMS_M5_Cell_Thermistor_Data_3: 4 Custom_BMS
SG_ BMS_M5_Cell_position9_Thermistor  : 0|16@1+ (1,0) [0|255] "C" Custom_BMS
SG_ BMS_M5_Cell_position10_Thermistor : 16|16@1+ (1,0) [0|255] "C" Custom_BMS CM_check thermister 10 readings

BO_ 1679 BMS_M6_Cell_Thermistor_Data_1: 8 Custom_BMS
SG_ BMS_M6_Cell_position1_Thermistor : 0|16@1+ (1,0) [0|255] "C" Custom_BMS
SG_ BMS_M6_Cell_position2_Thermistor : 16|16@1+ (1,0) [0|255] "C" Custom_BMS
SG_ BMS_M6_Cell_position3_Thermistor : 32|16@1+ (1,0) [0|255] "C" Custom_BMS
SG_ BMS_M6_Cell_position4_Thermistor : 48|16@1+ (1,0) [0|255] "C" Custom_BMS

BO_ 1680 BMS_M6_Cell_Thermistor_Data_2: 8 Custom_BMS
SG_ BMS_M6_Cell_position5_Thermistor : 0|16@1+ (1,0) [0|255] "C" Custom_BMS
SG_ BMS_M6_Cell_position6_Thermistor : 16|16@1+ (1,0) [0|255] "C" Custom_BMS
SG_ BMS_M6_Cell_position7_Thermistor : 32|16@1+ (1,0) [0|255] "C" Custom_BMS
SG_ BMS_M6_Cell_position8_Thermistor : 48|16@1+ (1,0) [0|255] "C" Custom_BMS

BO_ 1681 BMS_M6_Cell_Thermistor_Data_3: 4 Custom_BMS
SG_ BMS_M6_Cell_position9_Thermistor  : 0|16@1+ (1,0) [0|255] "C" Custom_BMS
SG_ BMS_M6_Cell_position10_Thermistor : 16|16@1+ (1,0) [0|255] "C" Custom_BMS CM_check thermister 10 readings

BO_ 1682 BMS_M7_Cell_Thermistor_Data_1: 8 Custom_BMS
SG_ BMS_M7_Cell_position1_Thermistor : 0|16@1+ (1,0) [0|255] "C" Custom_BMS
SG_ BMS_M7_Cell_position2_Thermistor : 16|16@1+ (1,0) [0|255] "C" Custom_BMS
SG_ BMS_M7_Cell_position3_Thermistor : 32|16@1+ (1,0) [0|255] "C" Custom_BMS
SG_ BMS_M7_Cell_position4_Thermistor : 48|16@1+ (1,0) [0|255] "C" Custom_BMS

BO_ 1683 BMS_M7_Cell_Thermistor_Data_2: 8 Custom_BMS
SG_ BMS_M7_Cell_position5_Thermistor : 0|16@1+ (1,0) [0|255] "C" Custom_BMS
SG_ BMS_M7_Cell_position6_Thermistor : 16|16@1+ (1,0) [0|255] "C" Custom_BMS
SG_ BMS_M7_Cell_position7_Thermistor : 32|16@1+ (1,0) [0|255] "C" Custom_BMS
SG_ BMS_M7_Cell_position8_Thermistor : 48|16@1+ (1,0) [0|255] "C" Custom_BMS

BO_ 1684 BMS_M7_Cell_Thermistor_Data_3: 4 Custom_BMS
SG_ BMS_M7_Cell_position9_Thermistor  : 0|16@1+ (1,0) [0|255] "C" Custom_BMS
SG_ BMS_M7_Cell_position10_Thermistor : 16|16@1+ (1,0) [0|255] "C" Custom_BMS CM_check thermister 10 readings

BO_ 1685 BMS_M8_Cell_Thermistor_Data_1: 8 Custom_BMS
SG_ BMS_M8_Cell_position1_Thermistor : 0|16@1+ (1,0) [0|255] "C" Custom_BMS
SG_ BMS_M8_Cell_position2_Thermistor : 16|16@1+ (1,0) [0|255] "C" Custom_BMS
SG_ BMS_M8_Cell_position3_Thermistor : 32|16@1+ (1,0) [0|255] "C" Custom_BMS
SG_ BMS_M8_Cell_position4_Thermistor : 48|16@1+ (1,0) [0|255] "C" Custom_BMS

BO_ 1686 BMS_M8_Cell_Thermistor_Data_2: 8 Custom_BMS
SG_ BMS_M8_Cell_position5_Thermistor : 0|16@1+ (1,0) [0|255] "C" Custom_BMS
SG_ BMS_M8_Cell_position6_Thermistor : 16|16@1+ (1,0) [0|255] "C" Custom_BMS
SG_ BMS_M8_Cell_position7_Thermistor : 32|16@1+ (1,0) [0|255] "C" Custom_BMS
SG_ BMS_M8_Cell_position8_Thermistor : 48|16@1+ (1,0) [0|255] "C" Custom_BMS

BO_ 1687 BMS_M8_Cell_Thermistor_Data_3: 4 Custom_BMS
SG_ BMS_M8_Cell_position9_Thermistor  : 0|16@1+ (1,0) [0|255] "C" Custom_BMS
SG_ BMS_M8_Cell_position10_Thermistor : 16|16@1+ (1,0) [0|255] "C" Custom_BMS CM_check thermister 10 readings

BO_ 1688 BMS_M9_Cell_Thermistor_Data_1: 8 Custom_BMS
SG_ BMS_M9_Cell_position1_Thermistor : 0|16@1+ (1,0) [0|255] "C" Custom_BMS
SG_ BMS_M9_Cell_position2_Thermistor : 16|16@1+ (1,0) [0|255] "C" Custom_BMS
SG_ BMS_M9_Cell_position3_Thermistor : 32|16@1+ (1,0) [0|255] "C" Custom_BMS
SG_ BMS_M9_Cell_position4_Thermistor : 48|16@1+ (1,0) [0|255] "C" Custom_BMS

BO_ 1689 BMS_M9_Cell_Thermistor_Data_2: 8 Custom_BMS
SG_ BMS_M9_Cell_position5_Thermistor : 0|16@1+ (1,0) [0|255] "C" Custom_BMS
SG_ BMS_M9_Cell_position6_Thermistor : 16|16@1+ (1,0) [0|255] "C" Custom_BMS
SG_ BMS_M9_Cell_position7_Thermistor : 32|16@1+ (1,0) [0|255] "C" Custom_BMS
SG_ BMS_M9_Cell_position8_Thermistor : 48|16@1+ (1,0) [0|255] "C" Custom_BMS

BO_ 1690 BMS_M9_Cell_Thermistor_Data_3: 4 Custom_BMS
SG_ BMS_M9_Cell_position9_Thermistor  : 0|16@1+ (1,0) [0|255] "C" Custom_BMS
SG_ BMS_M9_Cell_position10_Thermistor : 16|16@1+ (1,0) [0|255] "C" Custom_BMS

BO_ 1691 BMS_M10_Cell_Thermistor_Data_1: 8 Custom_BMS
SG_ BMS_M10_Cell_position1_Thermistor : 0|16@1+ (1,0) [0|255] "C" Custom_BMS
SG_ BMS_M10_Cell_position2_Thermistor : 16|16@1+ (1,0) [0|255] "C" Custom_BMS
SG_ BMS_M10_Cell_position3_Thermistor : 32|16@1+ (1,0) [0|255] "C" Custom_BMS
SG_ BMS_M10_Cell_position4_Thermistor : 48|16@1+ (1,0) [0|255] "C" Custom_BMS

BO_ 1692 BMS_M10_Cell_Thermistor_Data_2: 8 Custom_BMS
SG_ BMS_M10_Cell_position5_Thermistor : 0|16@1+ (1,0) [0|255] "C" Custom_BMS
SG_ BMS_M10_Cell_position6_Thermistor : 16|16@1+ (1,0) [0|255] "C" Custom_BMS
SG_ BMS_M10_Cell_position7_Thermistor : 32|16@1+ (1,0) [0|255] "C" Custom_BMS
SG_ BMS_M10_Cell_position8_Thermistor : 48|16@1+ (1,0) [0|255] "C" Custom_BMS

BO_ 1693 BMS_M10_Cell_Thermistor_Data_2: 4 Custom_BMS
SG_ BMS_M10_Cell_position9_Thermistor  : 0|16@1+ (1,0) [0|255] "C" Custom_BMS
SG_ BMS_M10_Cell_position10_Thermistor : 16|16@1+ (1,0) [0|255] "C" Custom_BMS

BO_ 1694 BMS_Faults_Message_1: 8 Custom_BMS
SG_ BMS_Enable_Balance_Message  : 0|1@1+ (0,0) [0|1] "" Custom_BMS
SG_ BMS_Cell_Overvolt_Fault	    : 1|1@1+ (0,0) [0|1] " " Custom_BMS
SG_ BMS_Cell_Undervolt_Fault	: 2|1@1+ (0,0) [0|1] " " Custom_BMS
SG_ BMS_Cell_High_Temp_Fault	: 3|1@1+ (0,0) [0|1] " " Custom_BMS
SG_ BMS_Cell_Low_Temp_Fault	    : 4|1@1+ (0,0) [0|1] " " Custom_BMS
SG_ BMS_Redundant_Voltage_Fault : 5|1@1+ (0,0) [0|1] " " Custom_BMS
SG_ BMS_Redundant_Temp_Fault	: 6|1@1+ (0,0) [0|1] " " Custom_BMS
SG_ BMS_Invalid_Data_Fault	    : 7|1@1+ (0,0) [0|1] " " Custom_BMS
SG_ BMS_Open_Wire_Detection_Fault : 8|1@1+ (0,0) [0|1] " " Custom_BMS CM_ added maybe use

BO_ 1695 BMS_Pack_Data : 2 Custom_BMS
SG_ MCU_Pressure  : 0|8@1+ (0.001, 0) [0|6.5535] " " Custom_BMS
SG_ MCU_Humidity  : 8|8@1+ (0.001, 0) [0|6.5535] " " Custom_BMS

B0_ 1696 BMS_Pack_Voltage_Data : 4 Custom_BMS
SG_ BMS_HVsens_Pack_Voltage : 0|16@1- (0.001,0) [-32.768|32.767] "V" Custom_BMS	CM_check have been moved and add max min imbalance, average volt
SG_ BMS_Sum_Pack_Voltage    : 16|16@1- (0.001,0) [-32.768|32.767] "V" Custom_BMS

BO_ 1697 BMS_avg_module_temp_1  : 8 Custom_BMS
SG_ BMS_avg_M1_Voltage : 0|16@1- (0.001,0) [-32.768|32.767] "V" Custom_BMS
SG_ BMS_avg_M2_Voltage : 16|16@1- (0.001,0) [-32.768|32.767] "V" Custom_BMS
SG_ BMS_avg_M3_Voltage : 32|16@1- (0.001,0) [-32.768|32.767] "V" Custom_BMS
SG_ BMS_avg_M4_Voltage : 48|16@1- (0.001,0) [-32.768|32.767] "V" Custom_BMS

BO_ 1698 BMS_avg_module_temp_2  : 8 Custom_BMS
SG_ BMS_avg_M5_Voltage : 0|16@1- (0.001,0) [-32.768|32.767] "V" Custom_BMS
SG_ BMS_avg_M6_Voltage : 16|16@1- (0.001,0) [-32.768|32.767] "V" Custom_BMS
SG_ BMS_avg_M7_Voltage : 32|16@1- (0.001,0) [-32.768|32.767] "V" Custom_BMS
SG_ BMS_avg_M8_Voltage : 48|16@1- (0.001,0) [-32.768|32.767] "V" Custom_BMS

BO_ 1699 BMS_avg_module_temp_3  : 4 Custom_BMS
SG_ BMS_avg_M9_Voltage : 0|16@1- (0.001,0) [-32.768|32.767] "V" Custom_BMS
SG_ BMS_avg_M10_Voltage: 16|16@1- (0.001,0) [-32.768|32.767] "V" Custom_BMS

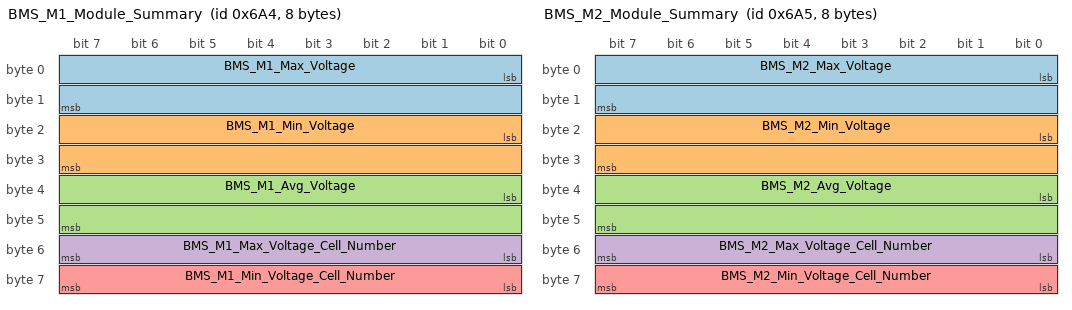
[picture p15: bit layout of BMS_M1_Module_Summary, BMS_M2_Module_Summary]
BO_ 1700 BMS_M1_Module_Summary  : 8 Custom_BMS
SG_ BMS_M1_Max_Voltage 	  : 0|16@1- (0.001,0) [-32.768|32.767] "V" Custom_BMS
SG_ BMS_M1_Min_Voltage 	  : 16|16@1- (0.001,0) [-32.768|32.767] "V" Custom_BMS
SG_ BMS_M1_Avg_Voltage 	  : 32|16@1- (0.001,0) [-32.768|32.767] "V" Custom_BMS
SG_ BMS_M1_Max_Voltage_Cell_Number : 48|8@1+ (1,0) [0|255] "" Custom_BMS
SG_ BMS_M1_Min_Voltage_Cell_Number : 56|8@1+ (1,0) [0|255] "" Custom_BMS

BO_ 1701 BMS_M2_Module_Summary  : 8 Custom_BMS
SG_ BMS_M2_Max_Voltage 	  : 0|16@1- (0.001,0) [-32.768|32.767] "V" Custom_BMS
SG_ BMS_M2_Min_Voltage 	  : 16|16@1- (0.001,0) [-32.768|32.767] "V" Custom_BMS
SG_ BMS_M2_Avg_Voltage 	  : 32|16@1- (0.001,0) [-32.768|32.767] "V" Custom_BMS
SG_ BMS_M2_Max_Voltage_Cell_Number : 48|8@1+ (0.001,0) [0|6.5535] "" Custom_BMS
SG_ BMS_M2_Min_Voltage_Cell_Number : 56|8@1+ (0.001,0) [0|6.5535] "" Custom_BMS

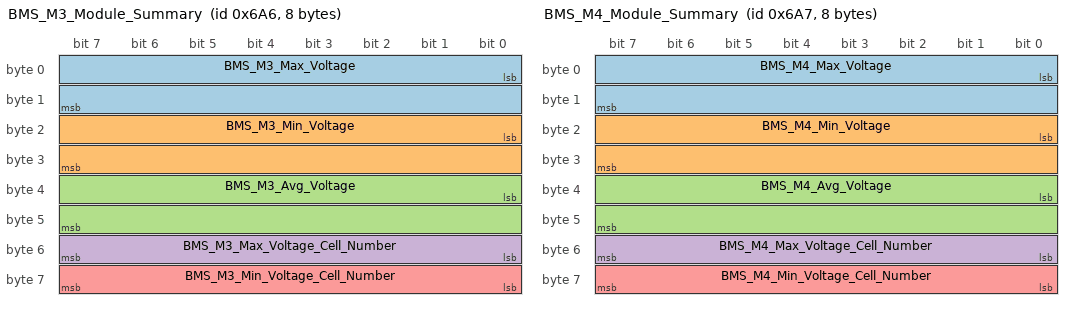
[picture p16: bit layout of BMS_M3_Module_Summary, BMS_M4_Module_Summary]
BO_ 1702 BMS_M3_Module_Summary  : 8 Custom_BMS
SG_ BMS_M3_Max_Voltage 	  : 0|16@1- (0.001,0) [-32.768|32.767] "V" Custom_BMS
SG_ BMS_M3_Min_Voltage 	  : 16|16@1- (0.001,0) [-32.768|32.767] "V" Custom_BMS
SG_ BMS_M3_Avg_Voltage 	  : 32|16@1- (0.001,0) [-32.768|32.767] "V" Custom_BMS
SG_ BMS_M3_Max_Voltage_Cell_Number : 48|8@1+ (0.001,0) [0|6.5535] "" Custom_BMS
SG_ BMS_M3_Min_Voltage_Cell_Number : 56|8@1+ (0.001,0) [0|6.5535] "" Custom_BMS

BO_ 1703 BMS_M4_Module_Summary  : 8 Custom_BMS
SG_ BMS_M4_Max_Voltage 	  : 0|16@1- (0.001,0) [-32.768|32.767] "V" Custom_BMS
SG_ BMS_M4_Min_Voltage 	  : 16|16@1- (0.001,0) [-32.768|32.767] "V" Custom_BMS
SG_ BMS_M4_Avg_Voltage 	  : 32|16@1- (0.001,0) [-32.768|32.767] "V" Custom_BMS
SG_ BMS_M4_Max_Voltage_Cell_Number : 48|8@1+ (0.001,0) [0|6.5535] "" Custom_BMS
SG_ BMS_M4_Min_Voltage_Cell_Number : 56|8@1+ (0.001,0) [0|6.5535] "" Custom_BMS

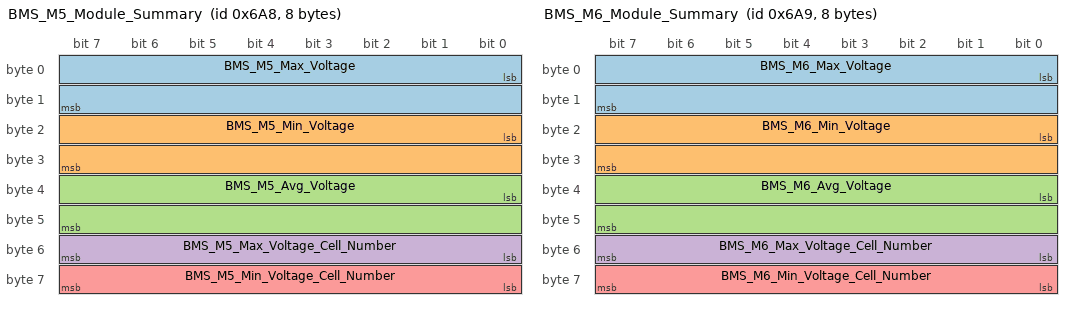
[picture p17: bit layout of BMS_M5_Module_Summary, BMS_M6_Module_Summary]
BO_ 1704 BMS_M5_Module_Summary  : 8 Custom_BMS
SG_ BMS_M5_Max_Voltage 	  : 0|16@1- (0.001,0) [-32.768|32.767] "V" Custom_BMS
SG_ BMS_M5_Min_Voltage 	  : 16|16@1- (0.001,0) [-32.768|32.767] "V" Custom_BMS
SG_ BMS_M5_Avg_Voltage 	  : 32|16@1- (0.001,0) [-32.768|32.767] "V" Custom_BMS
SG_ BMS_M5_Max_Voltage_Cell_Number : 48|8@1+ (0.001,0) [0|6.5535] "" Custom_BMS
SG_ BMS_M5_Min_Voltage_Cell_Number : 56|8@1+ (0.001,0) [0|6.5535] "" Custom_BMS

BO_ 1705 BMS_M6_Module_Summary  : 8 Custom_BMS
SG_ BMS_M6_Max_Voltage 	  : 0|16@1- (0.001,0) [-32.768|32.767] "V" Custom_BMS
SG_ BMS_M6_Min_Voltage 	  : 16|16@1- (0.001,0) [-32.768|32.767] "V" Custom_BMS
SG_ BMS_M6_Avg_Voltage 	  : 32|16@1- (0.001,0) [-32.768|32.767] "V" Custom_BMS
SG_ BMS_M6_Max_Voltage_Cell_Number : 48|8@1+ (0.001,0) [0|6.5535] "" Custom_BMS
SG_ BMS_M6_Min_Voltage_Cell_Number : 56|8@1+ (0.001,0) [0|6.5535] "" Custom_BMS

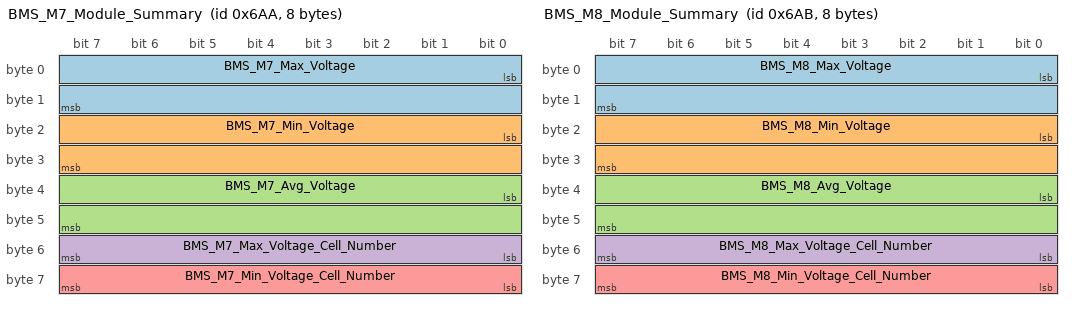
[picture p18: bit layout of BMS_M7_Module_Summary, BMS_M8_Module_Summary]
BO_ 1706 BMS_M7_Module_Summary  : 8 Custom_BMS
SG_ BMS_M7_Max_Voltage 	  : 0|16@1- (0.001,0) [-32.768|32.767] "V" Custom_BMS
SG_ BMS_M7_Min_Voltage 	  : 16|16@1- (0.001,0) [-32.768|32.767] "V" Custom_BMS
SG_ BMS_M7_Avg_Voltage 	  : 32|16@1- (0.001,0) [-32.768|32.767] "V" Custom_BMS
SG_ BMS_M7_Max_Voltage_Cell_Number : 48|8@1+ (0.001,0) [0|6.5535] "" Custom_BMS
SG_ BMS_M7_Min_Voltage_Cell_Number : 56|8@1+ (0.001,0) [0|6.5535] "" Custom_BMS

BO_ 1707 BMS_M8_Module_Summary  : 8 Custom_BMS
SG_ BMS_M8_Max_Voltage 	  : 0|16@1- (0.001,0) [-32.768|32.767] "V" Custom_BMS
SG_ BMS_M8_Min_Voltage 	  : 16|16@1- (0.001,0) [-32.768|32.767] "V" Custom_BMS
SG_ BMS_M8_Avg_Voltage 	  : 32|16@1- (0.001,0) [-32.768|32.767] "V" Custom_BMS
SG_ BMS_M8_Max_Voltage_Cell_Number : 48|8@1+ (0.001,0) [0|6.5535] "" Custom_BMS
SG_ BMS_M8_Min_Voltage_Cell_Number : 56|8@1+ (0.001,0) [0|6.5535] "" Custom_BMS

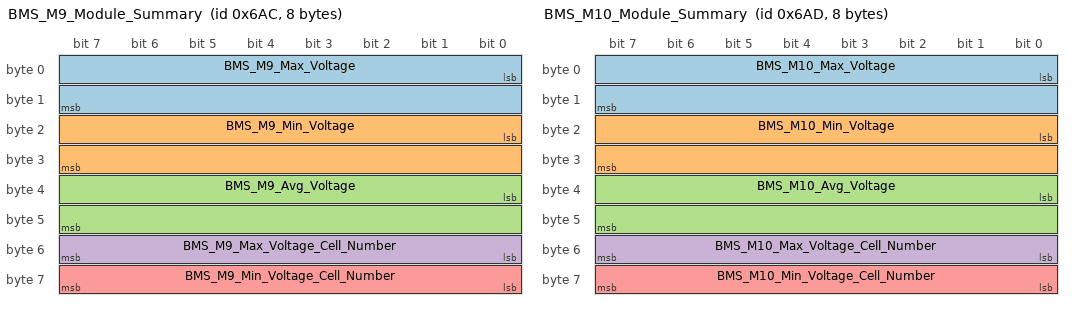
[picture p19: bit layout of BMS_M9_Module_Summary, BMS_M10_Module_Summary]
BO_ 1708 BMS_M9_Module_Summary  : 8 Custom_BMS
SG_ BMS_M9_Max_Voltage 	  : 0|16@1- (0.001,0) [-32.768|32.767] "V" Custom_BMS
SG_ BMS_M9_Min_Voltage 	  : 16|16@1- (0.001,0) [-32.768|32.767] "V" Custom_BMS
SG_ BMS_M9_Avg_Voltage 	  : 32|16@1- (0.001,0) [-32.768|32.767] "V" Custom_BMS
SG_ BMS_M9_Max_Voltage_Cell_Number : 48|8@1+ (0.001,0) [0|6.5535] "" Custom_BMS
SG_ BMS_M9_Min_Voltage_Cell_Number : 56|8@1+ (0.001,0) [0|6.5535] "" Custom_BMS

BO_ 1709 BMS_M10_Module_Summary  : 8 Custom_BMS
SG_ BMS_M10_Max_Voltage 	: 0|16@1- (0.001,0) [-32.768|32.767] "V" Custom_BMS
SG_ BMS_M10_Min_Voltage 	: 16|16@1- (0.001,0) [-32.768|32.767] "V" Custom_BMS
SG_ BMS_M10_Avg_Voltage 	: 32|16@1- (0.001,0) [-32.768|32.767] "V" Custom_BMS
SG_ BMS_M10_Max_Voltage_Cell_Number  : 48|8@1+ (0.001,0) [0|6.5535] "" Custom_BMS
SG_ BMS_M10_Min_Voltage_Cell_Number  : 56|8@1+ (0.001,0) [0|6.5535] "" Custom_BMS

BO_ 1710 BMS_Fault_Status_M1_to_M4  : 8 Custom_BMS
SG_ BMS_M1_Cell_1_Fault 	: 0|1@1+ (1,0) [0|1] "" Custom_BMS
SG_ BMS_M1_Cell_2_Fault  	: 1|1@1+ (1,0) [0|1] "" Custom_BMS
SG_ BMS_M1_Cell_3_Fault  	: 2|1@1+ (1,0) [0|1] "" Custom_BMS
SG_ BMS_M1_Cell_4_Fault   	: 3|1@1+ (1,0) [0|1] "" Custom_BMS
SG_ BMS_M1_Cell_5_Fault   	: 4|1@1+ (1,0) [0|1] "" Custom_BMS
SG_ BMS_M1_Cell_6_Fault 	: 5|1@1+ (1,0) [0|1] "" Custom_BMS
SG_ BMS_M1_Cell_7_Fault  	: 6|1@1+ (1,0) [0|1] "" Custom_BMS
SG_ BMS_M1_Cell_8_Fault  	: 7|1@1+ (1,0) [0|1] "" Custom_BMS
SG_ BMS_M1_Cell_9_Fault   	: 8|1@1+ (1,0) [0|1] "" Custom_BMS
SG_ BMS_M1_Cell_10_Fault   	: 9|1@1+ (1,0) [0|1] "" Custom_BMS
SG_ BMS_M1_Cell_11_Fault 	: 10|1@1+ (1,0) [0|1] "" Custom_BMS
SG_ BMS_M1_Cell_12_Fault  	: 11|1@1+ (1,0) [0|1] "" Custom_BMS
SG_ BMS_M1_Cell_13_Fault  	: 12|1@1+ (1,0) [0|1] "" Custom_BMS
SG_ BMS_M1_Cell_14_Fault   	: 13|1@1+ (1,0) [0|1] "" Custom_BMS
SG_ BMS_M2_Cell_1_Fault   	: 16|1@1+ (1,0) [0|1] "" Custom_BMS
SG_ BMS_M2_Cell_2_Fault 	: 17|1@1+ (1,0) [0|1] "" Custom_BMS
SG_ BMS_M2_Cell_3_Fault  	: 18|1@1+ (1,0) [0|1] "" Custom_BMS
SG_ BMS_M2_Cell_4_Fault  	: 19|1@1+ (1,0) [0|1] "" Custom_BMS
SG_ BMS_M2_Cell_5_Fault   	: 20|1@1+ (1,0) [0|1] "" Custom_BMS
SG_ BMS_M2_Cell_6_Fault   	: 21|1@1+ (1,0) [0|1] "" Custom_BMS
SG_ BMS_M2_Cell_7_Fault  	: 22|1@1+ (1,0) [0|1] "" Custom_BMS
SG_ BMS_M2_Cell_8_Fault  	: 23|1@1+ (1,0) [0|1] "" Custom_BMS
SG_ BMS_M2_Cell_9_Fault   	: 24|1@1+ (1,0) [0|1] "" Custom_BMS
SG_ BMS_M2_Cell_10_Fault   	: 25|1@1+ (1,0) [0|1] "" Custom_BMS
SG_ BMS_M2_Cell_11_Fault 	: 26|1@1+ (1,0) [0|1] "" Custom_BMS
SG_ BMS_M2_Cell_12_Fault  	: 27|1@1+ (1,0) [0|1] "" Custom_BMS
SG_ BMS_M2_Cell_13_Fault  	: 28|1@1+ (1,0) [0|1] "" Custom_BMS
SG_ BMS_M2_Cell_14_Fault   	: 29|1@1+ (1,0) [0|1] "" Custom_BMS
SG_ BMS_M3_Cell_1_Fault   	: 32|1@1+ (1,0) [0|1] "" Custom_BMS
SG_ BMS_M3_Cell_2_Fault 	: 33|1@1+ (1,0) [0|1] "" Custom_BMS
SG_ BMS_M3_Cell_3_Fault  	: 34|1@1+ (1,0) [0|1] "" Custom_BMS
SG_ BMS_M3_Cell_4_Fault  	: 35|1@1+ (1,0) [0|1] "" Custom_BMS
SG_ BMS_M3_Cell_5_Fault   	: 36|1@1+ (1,0) [0|1] "" Custom_BMS
SG_ BMS_M3_Cell_6_Fault   	: 37|1@1+ (1,0) [0|1] "" Custom_BMS
SG_ BMS_M3_Cell_7_Fault  	: 38|1@1+ (1,0) [0|1] "" Custom_BMS
SG_ BMS_M3_Cell_8_Fault  	: 39|1@1+ (1,0) [0|1] "" Custom_BMS
SG_ BMS_M3_Cell_9_Fault   	: 40|1@1+ (1,0) [0|1] "" Custom_BMS
SG_ BMS_M3_Cell_10_Fault   	: 41|1@1+ (1,0) [0|1] "" Custom_BMS
SG_ BMS_M3_Cell_11_Fault 	: 42|1@1+ (1,0) [0|1] "" Custom_BMS
SG_ BMS_M3_Cell_12_Fault  	: 43|1@1+ (1,0) [0|1] "" Custom_BMS
SG_ BMS_M3_Cell_13_Fault  	: 44|1@1+ (1,0) [0|1] "" Custom_BMS
SG_ BMS_M3_Cell_14_Fault   	: 45|1@1+ (1,0) [0|1] "" Custom_BMS
SG_ BMS_M4_Cell_1_Fault   	: 48|1@1+ (1,0) [0|1] "" Custom_BMS
SG_ BMS_M4_Cell_2_Fault 	: 49|1@1+ (1,0) [0|1] "" Custom_BMS
SG_ BMS_M4_Cell_3_Fault  	: 50|1@1+ (1,0) [0|1] "" Custom_BMS
SG_ BMS_M4_Cell_4_Fault  	: 51|1@1+ (1,0) [0|1] "" Custom_BMS
SG_ BMS_M4_Cell_5_Fault   	: 52|1@1+ (1,0) [0|1] "" Custom_BMS
SG_ BMS_M4_Cell_6_Fault   	: 53|1@1+ (1,0) [0|1] "" Custom_BMS
SG_ BMS_M4_Cell_7_Fault  	: 54|1@1+ (1,0) [0|1] "" Custom_BMS
SG_ BMS_M4_Cell_8_Fault  	: 55|1@1+ (1,0) [0|1] "" Custom_BMS
SG_ BMS_M4_Cell_9_Fault   	: 56|1@1+ (1,0) [0|1] "" Custom_BMS
SG_ BMS_M4_Cell_10_Fault   	: 57|1@1+ (1,0) [0|1] "" Custom_BMS
SG_ BMS_M4_Cell_11_Fault 	: 58|1@1+ (1,0) [0|1] "" Custom_BMS
SG_ BMS_M4_Cell_12_Fault  	: 59|1@1+ (1,0) [0|1] "" Custom_BMS
SG_ BMS_M4_Cell_13_Fault  	: 60|1@1+ (1,0) [0|1] "" Custom_BMS
SG_ BMS_M4_Cell_14_Fault   	: 61|1@1+ (1,0) [0|1] "" Custom_BMS

BO_ 1711 BMS_Fault_Status_M5_to_M8  : 8 Custom_BMS
SG_ BMS_M5_Cell_1_Fault 	: 0|1@1+ (1,0) [0|1] "" Custom_BMS
SG_ BMS_M5_Cell_2_Fault  	: 1|1@1+ (1,0) [0|1] "" Custom_BMS
SG_ BMS_M5_Cell_3_Fault  	: 2|1@1+ (1,0) [0|1] "" Custom_BMS
SG_ BMS_M5_Cell_4_Fault   	: 3|1@1+ (1,0) [0|1] "" Custom_BMS
SG_ BMS_M5_Cell_5_Fault   	: 4|1@1+ (1,0) [0|1] "" Custom_BMS
SG_ BMS_M5_Cell_6_Fault 	: 5|1@1+ (1,0) [0|1] "" Custom_BMS
SG_ BMS_M5_Cell_7_Fault  	: 6|1@1+ (1,0) [0|1] "" Custom_BMS
SG_ BMS_M5_Cell_8_Fault  	: 7|1@1+ (1,0) [0|1] "" Custom_BMS
SG_ BMS_M5_Cell_9_Fault   	: 8|1@1+ (1,0) [0|1] "" Custom_BMS
SG_ BMS_M5_Cell_10_Fault   	: 9|1@1+ (1,0) [0|1] "" Custom_BMS
SG_ BMS_M5_Cell_11_Fault 	: 10|1@1+ (1,0) [0|1] "" Custom_BMS
SG_ BMS_M5_Cell_12_Fault  	: 11|1@1+ (1,0) [0|1] "" Custom_BMS
SG_ BMS_M5_Cell_13_Fault  	: 12|1@1+ (1,0) [0|1] "" Custom_BMS
SG_ BMS_M5_Cell_14_Fault   	: 13|1@1+ (1,0) [0|1] "" Custom_BMS
SG_ BMS_M6_Cell_1_Fault   	: 16|1@1+ (1,0) [0|1] "" Custom_BMS
SG_ BMS_M6_Cell_2_Fault 	: 17|1@1+ (1,0) [0|1] "" Custom_BMS
SG_ BMS_M6_Cell_3_Fault  	: 18|1@1+ (1,0) [0|1] "" Custom_BMS
SG_ BMS_M6_Cell_4_Fault  	: 19|1@1+ (1,0) [0|1] "" Custom_BMS
SG_ BMS_M6_Cell_5_Fault   	: 20|1@1+ (1,0) [0|1] "" Custom_BMS
SG_ BMS_M6_Cell_6_Fault   	: 21|1@1+ (1,0) [0|1] "" Custom_BMS
SG_ BMS_M6_Cell_7_Fault  	: 22|1@1+ (1,0) [0|1] "" Custom_BMS
SG_ BMS_M6_Cell_8_Fault  	: 23|1@1+ (1,0) [0|1] "" Custom_BMS
SG_ BMS_M6_Cell_9_Fault   	: 24|1@1+ (1,0) [0|1] "" Custom_BMS
SG_ BMS_M6_Cell_10_Fault   	: 25|1@1+ (1,0) [0|1] "" Custom_BMS
SG_ BMS_M6_Cell_11_Fault 	: 26|1@1+ (1,0) [0|1] "" Custom_BMS
SG_ BMS_M6_Cell_12_Fault  	: 27|1@1+ (1,0) [0|1] "" Custom_BMS
SG_ BMS_M6_Cell_13_Fault  	: 28|1@1+ (1,0) [0|1] "" Custom_BMS
SG_ BMS_M6_Cell_14_Fault   	: 29|1@1+ (1,0) [0|1] "" Custom_BMS
SG_ BMS_M7_Cell_1_Fault   	: 32|1@1+ (1,0) [0|1] "" Custom_BMS
SG_ BMS_M7_Cell_2_Fault 	: 33|1@1+ (1,0) [0|1] "" Custom_BMS
SG_ BMS_M7_Cell_3_Fault  	: 34|1@1+ (1,0) [0|1] "" Custom_BMS
SG_ BMS_M7_Cell_4_Fault  	: 35|1@1+ (1,0) [0|1] "" Custom_BMS
SG_ BMS_M7_Cell_5_Fault   	: 36|1@1+ (1,0) [0|1] "" Custom_BMS
SG_ BMS_M7_Cell_6_Fault   	: 37|1@1+ (1,0) [0|1] "" Custom_BMS
SG_ BMS_M7_Cell_7_Fault  	: 38|1@1+ (1,0) [0|1] "" Custom_BMS
SG_ BMS_M7_Cell_8_Fault  	: 39|1@1+ (1,0) [0|1] "" Custom_BMS
SG_ BMS_M7_Cell_9_Fault   	: 40|1@1+ (1,0) [0|1] "" Custom_BMS
SG_ BMS_M7_Cell_10_Fault   	: 41|1@1+ (1,0) [0|1] "" Custom_BMS
SG_ BMS_M7_Cell_11_Fault 	: 42|1@1+ (1,0) [0|1] "" Custom_BMS
SG_ BMS_M7_Cell_12_Fault  	: 43|1@1+ (1,0) [0|1] "" Custom_BMS
SG_ BMS_M7_Cell_13_Fault  	: 44|1@1+ (1,0) [0|1] "" Custom_BMS
SG_ BMS_M7_Cell_14_Fault   	: 45|1@1+ (1,0) [0|1] "" Custom_BMS
SG_ BMS_M8_Cell_1_Fault   	: 48|1@1+ (1,0) [0|1] "" Custom_BMS
SG_ BMS_M8_Cell_2_Fault 	: 49|1@1+ (1,0) [0|1] "" Custom_BMS
SG_ BMS_M8_Cell_3_Fault  	: 50|1@1+ (1,0) [0|1] "" Custom_BMS
SG_ BMS_M8_Cell_4_Fault  	: 51|1@1+ (1,0) [0|1] "" Custom_BMS
SG_ BMS_M8_Cell_5_Fault   	: 52|1@1+ (1,0) [0|1] "" Custom_BMS
SG_ BMS_M8_Cell_6_Fault   	: 53|1@1+ (1,0) [0|1] "" Custom_BMS
SG_ BMS_M8_Cell_7_Fault  	: 54|1@1+ (1,0) [0|1] "" Custom_BMS
SG_ BMS_M8_Cell_8_Fault  	: 55|1@1+ (1,0) [0|1] "" Custom_BMS
SG_ BMS_M8_Cell_9_Fault   	: 56|1@1+ (1,0) [0|1] "" Custom_BMS
SG_ BMS_M8_Cell_10_Fault   	: 57|1@1+ (1,0) [0|1] "" Custom_BMS
SG_ BMS_M8_Cell_11_Fault 	: 58|1@1+ (1,0) [0|1] "" Custom_BMS
SG_ BMS_M8_Cell_12_Fault  	: 59|1@1+ (1,0) [0|1] "" Custom_BMS
SG_ BMS_M8_Cell_13_Fault  	: 60|1@1+ (1,0) [0|1] "" Custom_BMS
SG_ BMS_M8_Cell_14_Fault   	: 61|1@1+ (1,0) [0|1] "" Custom_BMS

BO_ 1712 BMS_Fault_Status_M9_to_M10  : 8 Custom_BMS
SG_ BMS_M9_Cell_1_Fault 	: 0|1@1+ (1,0) [0|1] "" Custom_BMS
SG_ BMS_M9_Cell_2_Fault  	: 1|1@1+ (1,0) [0|1] "" Custom_BMS
SG_ BMS_M9_Cell_3_Fault  	: 2|1@1+ (1,0) [0|1] "" Custom_BMS
SG_ BMS_M9_Cell_4_Fault   	: 3|1@1+ (1,0) [0|1] "" Custom_BMS
SG_ BMS_M9_Cell_5_Fault   	: 4|1@1+ (1,0) [0|1] "" Custom_BMS
SG_ BMS_M9_Cell_6_Fault 	: 5|1@1+ (1,0) [0|1] "" Custom_BMS
SG_ BMS_M9_Cell_7_Fault  	: 6|1@1+ (1,0) [0|1] "" Custom_BMS
SG_ BMS_M9_Cell_8_Fault  	: 7|1@1+ (1,0) [0|1] "" Custom_BMS
SG_ BMS_M9_Cell_9_Fault   	: 8|1@1+ (1,0) [0|1] "" Custom_BMS
SG_ BMS_M9_Cell_10_Fault   	: 9|1@1+ (1,0) [0|1] "" Custom_BMS
SG_ BMS_M9_Cell_11_Fault 	: 10|1@1+ (1,0) [0|1] "" Custom_BMS
SG_ BMS_M9_Cell_12_Fault  	: 11|1@1+ (1,0) [0|1] "" Custom_BMS
SG_ BMS_M9_Cell_13_Fault  	: 12|1@1+ (1,0) [0|1] "" Custom_BMS
SG_ BMS_M9_Cell_14_Fault   	: 13|1@1+ (1,0) [0|1] "" Custom_BMS
SG_ BMS_M10_Cell_1_Fault   	: 16|1@1+ (1,0) [0|1] "" Custom_BMS
SG_ BMS_M10_Cell_2_Fault 	: 17|1@1+ (1,0) [0|1] "" Custom_BMS
SG_ BMS_M10_Cell_3_Fault  	: 18|1@1+ (1,0) [0|1] "" Custom_BMS
SG_ BMS_M10_Cell_4_Fault  	: 19|1@1+ (1,0) [0|1] "" Custom_BMS
SG_ BMS_M10_Cell_5_Fault   	: 20|1@1+ (1,0) [0|1] "" Custom_BMS
SG_ BMS_M10_Cell_6_Fault   	: 21|1@1+ (1,0) [0|1] "" Custom_BMS
SG_ BMS_M10_Cell_7_Fault  	: 22|1@1+ (1,0) [0|1] "" Custom_BMS
SG_ BMS_M10_Cell_8_Fault  	: 23|1@1+ (1,0) [0|1] "" Custom_BMS
SG_ BMS_M10_Cell_9_Fault   	: 24|1@1+ (1,0) [0|1] "" Custom_BMS
SG_ BMS_M10_Cell_10_Fault   : 25|1@1+ (1,0) [0|1] "" Custom_BMS
SG_ BMS_M10_Cell_11_Fault 	: 26|1@1+ (1,0) [0|1] "" Custom_BMS
SG_ BMS_M10_Cell_12_Fault  	: 27|1@1+ (1,0) [0|1] "" Custom_BMS
SG_ BMS_M10_Cell_13_Fault  	: 28|1@1+ (1,0) [0|1] "" Custom_BMS
SG_ BMS_M10_Cell_14_Fault   : 29|1@1+ (1,0) [0|1] "" Custom_BMS

BO_ 1713 BMS_Heartbeat_Message  : 1 Custom_BMS
SG_ BMS_HeartBeat 	: 0|8@1+ (1,0) [0|1] "" Custom_BMS

BO_ 1714 BMS_Fault_And_Warning_Summary  : 8 Custom_BMS
SG_ BMS_Fault_Module_Id		: 0|8@1+ (1,0) [0|255] "" Custom_BMS
SG_ BMS_Fault_Cell_Id		: 8|8@1+ (1,0) [0|255] "" Custom_BMS
SG_ BMS_Fault_Over_Volt		: 16|1@1+ (1,0) [0|255] "" Custom_BMS
SG_ BMS_Fault_Under_Volt	: 17|1@1+ (1,0) [0|255] "" Custom_BMS
SG_ BMS_Fault_Open_Wire		: 18|1@1+ (1,0) [0|255] "" Custom_BMS
SG_ BMS_Fault_PEC			: 19|1@1+ (1,0) [0|255] "" Custom_BMS
SG_ BMS_Fault_Over_Temp		: 20|1@1+ (1,0) [0|255] "" Custom_BMS
SG_ BMS_Fault_Under_Temp	: 21|1@1+ (1,0) [0|255] "" Custom_BMS
SG_ BMS_Fault_Redundant_Volt: 22|1@1+ (1,0) [0|255] "" Custom_BMS
SG_ BMS_Fault_Redundant_Temp: 23|1@1+ (1,0) [0|255] "" Custom_BMS
SG_ BMS_Warning_Module_Id	: 24|8@1+ (1,0) [0|255] "" Custom_BMS
SG_ BMS_Warning_Cell_Id		: 32|8@1+ (1,0) [0|255] "" Custom_BMS
SG_ BMS_Warning_Over_Volt	: 40|1@1+ (1,0) [0|255] "" Custom_BMS
SG_ BMS_Warning_Under_Volt	: 41|1@1+ (1,0) [0|255] "" Custom_BMS
SG_ BMS_Warning_Over_Temp	: 42|1@1+ (1,0) [0|255] "" Custom_BMS
SG_ BMS_Warning_Under_Temp	: 43|1@1+ (1,0) [0|255] "" Custom_BMS
SG_ BMS_Warning_Imbalance	: 44|1@1+ (1,0) [0|255] "" Custom_BMS
